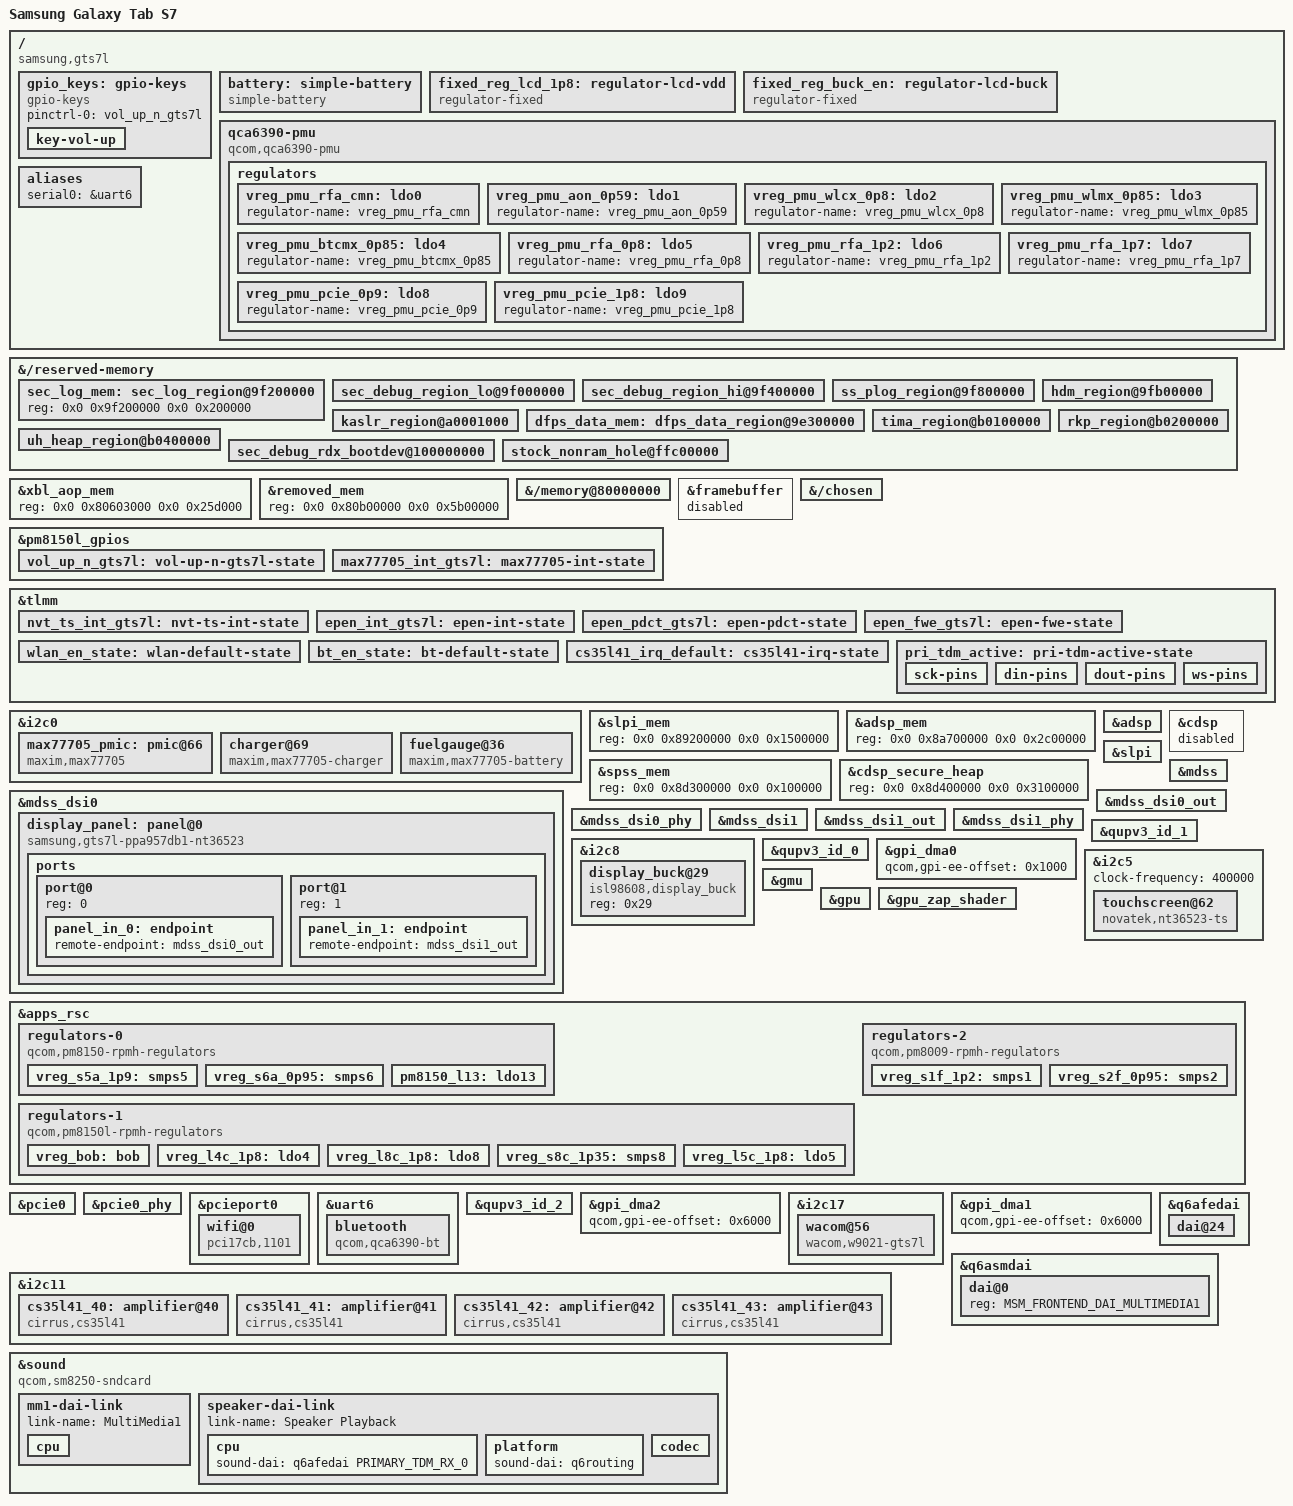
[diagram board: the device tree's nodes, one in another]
// SPDX-License-Identifier: GPL-2.0-only
/*
 * Samsung Galaxy Tab S7 LTE (SM-T875, "gts7l")
 *
 * Forked from upstream's sm8250-samsung-common.dtsi (shared Samsung SM8250
 * phone platform base: PM8150 PMIC, ADSP/CDSP/SLPI scaffolding, base
 * regulators) per the decision in docs/kernel-baseline.md. That base file is
 * phone-shaped (single volume-up key, phone-sized splash framebuffer) and is
 * overridden below wherever this tablet's actual hardware differs.
 *
 * Hardware facts below are sourced from two places, both cited inline:
 *   - Samsung's GPL kernel source for this device (T875XXU1ATK1),
 *     specifically the board-revision overlay that matches our physical
 *     unit's `androidboot.revision=7`:
 *     references/gts7l/arch/arm64/boot/dts/samsung/gts7l/
 *       kona-sec-gts7l-eur-overlay-r07.dts
 *   - Live confirmation pulled directly off the physical tablet (rooted,
 *     stock T875XXU1ATK4) via `cat /proc/interrupts` and
 *     `cat /sys/kernel/debug/gpio`, cross-checked against the above.
 * See docs/hardware-inventory.md and docs/devicetree-notes.md for the full
 * writeup and provenance of every value below. Anything not confirmed by
 * both sources is marked TODO rather than guessed.
 */

/dts-v1/;

#include <dt-bindings/gpio/gpio.h>
#include <dt-bindings/input/input.h>
#include <dt-bindings/interrupt-controller/irq.h>
#include <dt-bindings/phy/phy.h>
#include <dt-bindings/regulator/qcom,rpmh-regulator.h>
#include <dt-bindings/sound/qcom,q6asm.h>
#include "sm8250-samsung-common.dtsi"

/*
 * Unlike the Galaxy S20 phones sm8250-samsung-common.dtsi was written for,
 * this tablet has a full three-PMIC complex (PM8150 + PM8150L + PM8009),
 * confirmed in docs/hardware-inventory.md from Samsung's own GPL source.
 * common.dtsi only pulls in pm8150.dtsi - add the other two here so the
 * &pm8150l_gpios references below (volume-up, S Pen, MAX77705 irq - all
 * confirmed wired to PM8150L, not PM8150) resolve. Both self-attach to
 * &spmi_bus internally, so #include is all that's needed.
 */
#include "pm8150l.dtsi"
#include "pm8009.dtsi"

/ {
	model = "Samsung Galaxy Tab S7";
	/*
	 * RETRACTED 2026-09-13 (Round 7, docs/kernel-boot-debugging.md): this
	 * 3-entry structure was believed fixed based on indirect evidence that
	 * turned out to be a methodology artifact (same class of mistake as
	 * the "confirmed baseline" retraction elsewhere in this project). A
	 * correctly-built, freshly-tested artifact using exactly this DTS
	 * still hits the identical "No match found for Soc Dtb type" failure,
	 * at a timestamp identical to the microsecond versus every other
	 * variant tried (single-entry, with/without msm-id, with/without
	 * `-@`). The structure below is kept because it correctly mirrors
	 * stock's real appended-DTB layout and isn't known to be wrong - just
	 * not confirmed to be the fix. Root cause of the ABL rejection is
	 * unknown again; don't trust the "fix" framing in the comment below
	 * without re-reading Round 7 first.
	 */
	/*
	 * `qcom,kona` + `qcom,msm-id` fix attempt #2 (2026-09-13), after
	 * attempt #1 (DTS-property-only, single DTB) made zero observable
	 * difference to the "No match found for Soc Dtb type" failure - see
	 * docs/kernel-boot-debugging.md Round 5 for the full comparison.
	 *
	 * Root cause found by extracting the STOCK boot.img's own `dtb`
	 * section (via magiskboot unpack) and inspecting it directly: it is
	 * not one DTB, it's **three plain FDT blobs concatenated
	 * back-to-back** (FDT magic 0xd00dfeed found at byte offsets 0,
	 * 519810, 1039616 - confirmed by hand, not assumed), one per `kona`
	 * silicon stepping this retail unit's kernel expects to possibly see:
	 *
	 *   entry 0: model "kona v2.1 SoC", qcom,msm-id = <0x164 0x20001>
	 *   entry 1: model "kona v2 SoC",   qcom,msm-id = <0x164 0x20000>
	 *   entry 2: model "kona v1 SoC",   qcom,msm-id = <0x164 0x10000>
	 *
	 * All three use plain `compatible = "qcom,kona";` and none carry
	 * `qcom,board-id` at all (board-id belongs to a separate per-board
	 * dtbo overlay, applied later in the boot chain - Samsung's real
	 * overlay for this exact unit is
	 * references/gts7l/arch/arm64/boot/dts/samsung/gts7l/
	 * kona-sec-gts7l-eur-overlay-r07.dts, `qcom,board-id = <0x8 0x7>`).
	 * `qcom,board-id` is deliberately NOT set here for that reason - it
	 * doesn't belong in this stepping-selection blob per stock's own
	 * structure, and attempt #1 including it here proved that placement
	 * doesn't help anyway.
	 *
	 * Attempt #1's single DTB only covered the v1 (0x10000) stepping -
	 * if this physical unit's actual fused silicon revision is v2 or
	 * v2.1 (which stock clearly hedges for by shipping all three), a
	 * lone v1 entry would never match, exactly reproducing the
	 * unmodified failure we saw. The fix built from this DTS (see
	 * docs/kernel-boot-debugging.md Round 5) concatenates three
	 * otherwise-identical builds of this DTB, one per stepping, mirroring
	 * stock's exact structure - see work/build-appended-dtb.sh (or the
	 * Round 5 writeup) for how that's assembled from this single source
	 * file via `fdtput` patching qcom,msm-id per copy.
	 *
	 * Sourcing: stock dtb extraction done locally this session;
	 * cross-checked against Samsung's own base platform file
	 * (references/gts7l/arch/arm64/boot/dts/vendor/qcom/kona.dtsi,
	 * `compatible = "qcom,kona"` + `qcom,msm-id = <356 0x10000>` i.e.
	 * 0x164 0x10000 - matches stock entry 2 exactly) and against the
	 * sibling S9 Ultra project's independently-documented fix for the
	 * identical ABL error string on the same Samsung-ABL family
	 * (references/postmarketos-galaxy-tab-s9-ultra/docs/porting-log.md).
	 *
	 * qcom,board-id ADDED 2026-09-13 (Round 8, docs/kernel-boot-debugging.md):
	 * Qualcomm's own official binding doc (referenced kernel source,
	 * arch/arm64/boot/dts/vendor/bindings/arm/msm/msm-id.txt) states
	 * explicitly that the 2-field short form of qcom,msm-id used here
	 * ("chipset_foundry_id, rev_id") REQUIRES qcom,board-id to also be
	 * defined - a plain documented requirement this DTS was missing
	 * entirely, independent of and much simpler than every DTB-matching
	 * theory chased before it. Stock's own kona.dtsi entries confirm this
	 * requirement (they pair the same 2-field msm-id form with SOME
	 * qcom,board-id value) - fixing "No match found for Soc Dtb type"
	 * (confirmed in Round 9) only needed the property to be *present*,
	 * value `<0x00 0x00>` (wildcard) was sufficient for that specific
	 * check.
	 *
	 * Changed to the real value 2026-09-13 (Round 9, docs/kernel-boot-
	 * debugging.md): after the fix above, a *separate, later* ABL stage
	 * ("Unable to find the Board Dtb" / "Error: Board Dtbo blob not
	 * found") was hit and is NOT satisfied by the wildcard value - proven
	 * across three independent `dtbo` partition content variations (all
	 * produced byte-identical failures), meaning this stage reads board
	 * identity from the *appended DTB itself*, not `dtbo`, and requires
	 * an exact match. Set to `<0x08 0x07>`, this physical unit's real
	 * fused board-id - confirmed via the real per-board overlay in stock's
	 * dtbo.img (`entry.7`, `qcom,board-id = <0x08 0x07>`) and independently
	 * via TWRP's own kernel `Hardware name: Samsung GTS7L PROJECT - PV
	 * REV0.4 (board-id,7)` dmesg line. `0x8` is the platform-type-id field
	 * (constant across all stock's per-region entries), `0x7` the
	 * board-revision field (the value specific to this exact unit's
	 * region/revision). Four independent DTBO content variations (Round 9)
	 * all failed identically even with this value set, tracing further
	 * confirmed board-id alone isn't the remaining blocker.
	 *
	 * qcom,pmic-id ADDED 2026-09-13 (Round 9, via Ghidra decompilation of
	 * the actual ABL matching function, LinuxLoader.pe FUN_00025700):
	 * disassembly revealed ABL treats our appended-DTB match as only
	 * "good enough", not "exact" - an exact match (a specific 6-bit
	 * combination in the match-quality flags word) is required to skip
	 * the strict per-region DTBO search entirely, which is what's
	 * actually failing ("Unable to find the Board Dtb"). One of those
	 * required bits (bit 18) comes from qcom,pmic-id's first cell
	 * matching the live hardware PMIC "model" register exactly - a
	 * property this DTS never had, so that bit could never be set.
	 *
	 * Value: <0x1e 0 0 0> - `0x1e` from the live kernel's own
	 * /sys/devices/soc0/pmic_model (65566 = 0x1001E, low byte = 0x1E),
	 * the closest real evidence available without ABL's own verbose
	 * logging (blocked - needs raw uefivarstore partition writes to set
	 * the standard EDK2 "EFIDebug" variable, not attempted). Per the
	 * matcher's own logic, each of the 4 cells packs one PMIC's
	 * {model: low byte, revision: upper 3 bytes} and this device has 3
	 * real PMICs (PM8150/PM8150L/PM8009) - only cell 0 (the primary
	 * PMIC, matching what the Linux sysfs value itself reports) needs to
	 * be an exact model match for the specific bit we need; a model
	 * value of 0 in the other cells is treated as a harmless wildcard by
	 * the same matcher, not an error. **Not yet hardware-tested** - the
	 * exact correspondence between this Linux-reported value and what
	 * ABL's own hardware read returns is unproven; see
	 * kernel-boot-debugging.md Round 9 for the full reasoning and what
	 * to try next if this specific value doesn't work.
	 */
	compatible = "samsung,gts7l", "qcom,kona", "qcom,sm8250";
	qcom,msm-id = <0x164 0x10000>;
	qcom,board-id = <0x08 0x07>;
	qcom,pmic-id = <0x1e 0x00 0x00 0x00>;
	chassis-type = "tablet";

	/*
	 * RETRACTED 2026-09-19 (Round 22, docs/kernel-boot-debugging.md): the
	 * "regression" described below was real but the context has changed
	 * completely - back then this whole DTB was what ABL itself had to
	 * accept (Rounds 4-11's entire fight), so any content change could
	 * plausibly affect ABL's own matching. Since Round 20/22's uniLoader
	 * pivot, this DTB is never seen by ABL at all - it's embedded
	 * directly in uniLoader's own binary and only reaches the real
	 * mainline kernel after uniLoader has already gotten full CPU control
	 * from a completely unrelated, unmodified stock DTB/DTBO. There is no
	 * remaining mechanism by which content here could affect ABL
	 * acceptance. Re-adding the framebuffer override below on that basis.
	 *
	 * Original note (2026-09-12, Round 5-era): a `chosen`/
	 * `simple-framebuffer` node reusing the ABL's real splash region was
	 * tried to get an on-screen boot console, since neither
	 * `/proc/last_kmsg` (bootloader-only) nor `console-ramoops-0` (only
	 * ever reflects whichever kernel is *currently* running) can show
	 * what our kernel does after handoff. Reverted at the time after an
	 * isolation test showed a regression - not revisited until now,
	 * because at the time it wasn't understood *why*, and the DTB itself
	 * was still the thing ABL had to accept.
	 */
};

/*
 * Round 29 (2026-09-19, docs/kernel-boot-debugging.md): reserve Samsung's
 * real `sec_log_buf` region (`sec_log=0x200000@0x9F200000`, confirmed
 * live via this device's own `/proc/cmdline`) so the kernel's own memory
 * allocator can never hand this physical range out to anything else -
 * `init/main.c`'s `early_sec_log_init()` writes this project's own early
 * printk output directly into it, byte-compatible with the format
 * TWRP's own `/proc/last_kmsg` already reads. `no-map` isn't set
 * deliberately (matching stock's own splash-region convention elsewhere
 * in this file) - `early_sec_log_write()` accesses it via a plain
 * `phys_to_virt()`, which needs this region to stay part of the kernel's
 * ordinary linear map, not excluded from it.
 */
&{/reserved-memory} {
	sec_log_mem: sec_log_region@9f200000 {
		reg = <0x0 0x9f200000 0x0 0x200000>;
	};
};

/*
 * Round 34 (2026-09-19, docs/kernel-boot-debugging.md): the S9 Ultra
 * mainline porting project hit our exact symptom class (Linux boots,
 * console/logo visible, then dies with zero pstore/panic evidence) and
 * traced an early instance of it to `TZBSP_ERR_FATAL_NOC_ERROR` - Linux
 * touching a physical range Samsung's stock DTBO normally reserves but
 * their minimal upstream DTB didn't carry. Our own DTS has the same gap:
 * pulled this device's *live* `/reserved-memory` node straight off real
 * hardware (`adb shell` against a TWRP boot, which uses the same
 * ABL-merged stock DTB/DTBO as normal boot) and diffed it against what
 * upstream's `sm8250.dtsi` + `sm8250-samsung-common.dtsi` already
 * declare (`work/round34-reserved-mem/live-reserved-memory.txt`).
 *
 * Everything below is either populated by ABL/XBL/TrustZone before any
 * kernel choice is even made (so it's live/protected the same way
 * whether Samsung's downstream kernel or our own mainline one is
 * running), or is a case where upstream's own static node undershoots
 * what this specific device's firmware actually protects. The `pil_*`
 * remoteproc firmware regions were also compared and found shifted vs.
 * upstream, but were deliberately left alone: those addresses are only
 * ever touched by an active PIL/remoteproc driver requesting them, none
 * of which this Phase 1 kernel enables, and we have direct proof
 * (`docs/kernel-boot-debugging.md` Round 30+) that code executing from
 * uniLoader's own `PAYLOAD_ENTRY` - which happens to sit inside the
 * live `cdsp_secure_heap` range - runs correctly for many seconds, so
 * that particular overlap isn't hardware-enforced against us. These are:
 *
 *  - sec_debug_region@0x9f000000 (8 MiB) actually encloses our own
 *    sec_log_region above; reserved here as the two flanking pieces so
 *    the two nodes don't overlap.
 *  - ss_plog_region, hdm_region, kaslr_region: small, unconditional
 *    Samsung/TZ carveouts right next to sec_log/ramoops, entirely
 *    unreserved in our DTB until now.
 *  - dfps_data_region@0x9e300000 sits immediately after
 *    cont_splash_mem/our simple-framebuffer's own carveout ends -
 *    exactly the kind of neighbor worth reserving given our current
 *    unsolved "screen goes black right after simplefb registers"
 *    symptom.
 *  - tima_region/rkp_region/uh_heap_region: contiguous
 *    0xb0100000-0xb1800000, Samsung's kernel-protection carveouts.
 *  - sec_debug_rdx_bootdev@0x100000000: a large (173 MiB) live
 *    reservation with no upstream equivalent at all.
 */
&{/reserved-memory} {
	sec_debug_region_lo@9f000000 {
		reg = <0x0 0x9f000000 0x0 0x200000>;
		no-map;
	};

	sec_debug_region_hi@9f400000 {
		reg = <0x0 0x9f400000 0x0 0x400000>;
		no-map;
	};

	ss_plog_region@9f800000 {
		reg = <0x0 0x9f800000 0x0 0x200000>;
		no-map;
	};

	hdm_region@9fb00000 {
		reg = <0x0 0x9fb00000 0x0 0x1000>;
		no-map;
	};

	kaslr_region@a0001000 {
		reg = <0x0 0xa0001000 0x0 0x1000>;
		no-map;
	};

	dfps_data_region@9e300000 {
		reg = <0x0 0x9e300000 0x0 0x100000>;
		no-map;
	};

	tima_region@b0100000 {
		reg = <0x0 0xb0100000 0x0 0x100000>;
		no-map;
	};

	rkp_region@b0200000 {
		reg = <0x0 0xb0200000 0x0 0x200000>;
		no-map;
	};

	uh_heap_region@b0400000 {
		reg = <0x0 0xb0400000 0x0 0x1400000>;
		no-map;
	};

	sec_debug_rdx_bootdev@100000000 {
		reg = <0x1 0x00000000 0x0 0xad00000>;
		no-map;
	};
};

/*
 * Round 34: upstream's static `xbl_aop_mem`/`removed_mem` nodes both
 * undershoot what this device's live firmware actually protects -
 * confirmed via the same live `/reserved-memory` pull above. Real live
 * xbl_aop starts a full ~0xfd000 (~1 MiB) earlier than upstream's
 * `0x80700000`, and removed_mem is 0x800000 (8 MiB) bigger than
 * upstream's `0x5300000`. Overriding both by their upstream labels to
 * match the live values exactly, rather than adding overlapping nodes.
 */
&xbl_aop_mem {
	reg = <0x0 0x80603000 0x0 0x25d000>;
};

&removed_mem {
	reg = <0x0 0x80b00000 0x0 0x5b00000>;
};

/*
 * Round 23 (2026-09-19, docs/kernel-boot-debugging.md): pulled Samsung's
 * persistent `/dev/block/by-name/debug` ramdump-summary partition (a
 * genuine, real crash-history log spanning many prior resets - unlike
 * `/proc/last_kmsg`'s small ring buffer, found via online research the
 * owner asked for after confirming no UART hardware was available)
 * directly off the physical device from TWRP. It captured a real Linux
 * kernel panic from one of the Round 20-22 uniLoader boot attempts, with
 * a full backtrace pointing at `out_of_memory` / `__alloc_pages_nodemask`
 * / `handle_pte_fault` / `do_page_fault` - a real, textbook Linux
 * page-fault-triggers-allocation-triggers-OOM call chain, panic message
 * "System is deadlocked on memory". Root cause found directly:
 * upstream's `sm8250.dtsi` root `memory@80000000` node ships with
 * `reg = <0x0 0x80000000 0x0 0x0>` (zero size) and an explicit comment,
 * "We expect the bootloader to fill in the size" - normally patched
 * dynamically by ABL at boot time, but uniLoader's `patch_dtb()` only
 * ever adds `linux,initrd-start`/`-end`, never touches memory size. This
 * project's own compiled DTB confirmed carrying that exact zero-size
 * placeholder through unmodified. The real kernel was booting believing
 * it had zero bytes of usable RAM - a complete, sufficient explanation
 * for the observed OOM panic, independent of anything display/cmdline
 * related (Round 21-22's fixes never had a chance to matter). Real size
 * confirmed directly from this device's own hardware log
 * (`work/last_kmsg_*.txt`, XBL: "Rank 0 size = 6144 MB, Rank 1 size =
 * 0 MB"), base address matches the placeholder's own existing `0x80000000`.
 */
/*
 * PM8150 RTC (2026-09-22): the hardware clock exists and is enabled in
 * pm8150.dtsi, but was never usable - CONFIG_RTC_DRV_PM8XXX was =m (now
 * =y in kernel/config/gts7l.fragment), so there was no rtc0 at boot and
 * every boot started at 1970. It's read-only for Linux: tested with
 * allow-set-time, and the PMIC arbiter refused the write ("disallowed
 * SPMI write to sid=0, addr=0x6046" - write access belongs to another
 * execution environment, as on stock Android). So no allow-set-time
 * here; wall-clock time across reboots comes from a userspace offset
 * (tools/rootfs/rtc-offset/, same idea as Android's time daemon).
 */

&{/memory@80000000} {
	/*
	 * 2026-09-22 (CPU hard-hang investigation, docs/kernel-boot-debugging.md):
	 * the single flat 6 GiB range above was wrong. This device's live,
	 * ABL-filled `/proc/device-tree/memory/reg` (pulled from TWRP) is two
	 * ranges with a 52 MiB hole at 0xbcc00000-0xbfffffff, and stock's
	 * `/proc/iomem` agrees (System RAM ends at 0xbcbfffff, resumes at
	 * 0xc0000000). Our kernel was handing that hole out as ordinary pages.
	 * It sits below 4 GiB, so the page allocator only reaches it once
	 * ZONE_NORMAL is under pressure - or immediately with mem=2G - which
	 * matches the "memory pressure -> CPU stops answering even NMI" hang.
	 * Copied exactly from the live value.
	 */
	reg = <0x0 0x80000000 0x0 0x3cc00000>,
	      <0x0 0xc0000000 0x1 0x40000000>;
};

/*
 * 2026-09-22, same investigation: the other ranges a full diff of our
 * usable RAM against stock's `/proc/iomem` "System RAM" turned up (Round
 * 34 only diffed `/reserved-memory`, never the memory node or the actual
 * resulting RAM map):
 *
 *  - (The live `cdsp_secure_heap`, 0x90400000-0x94a00000, also differs
 *    from upstream's 0x8bf00000 node. A no-map node for it was tried and
 *    removed: it can't reserve because uniLoader's FDT already sits at
 *    ~0x939a8000 inside it, and ABL loading/running uniLoader from
 *    ~0x90600000-0x93a2xxxx shows that range is accessible at boot.)
 *  - 0xffc00000-0xffc1ffff (128 KiB) is inside ABL's memory range but
 *    excluded from stock's System RAM by something outside
 *    `/reserved-memory`; unknown owner, reserved to match stock.
 */
&{/reserved-memory} {
	stock_nonram_hole@ffc00000 {
		reg = <0x0 0xffc00000 0x0 0x20000>;
		no-map;
	};
};

/*
 * Round 22 (2026-09-19, docs/kernel-boot-debugging.md): uniLoader confirmed
 * working end to end on real hardware (its own splash/console prints
 * correctly, reaches "Booting kernel..." and jumps) - but nothing visible
 * happens after that, and there's no way yet to tell whether the real
 * kernel is silently working fine (just genuinely has no configured
 * console) or has crashed. Overriding the inherited phone-resolution
 * `framebuffer` node from `sm8250-samsung-common.dtsi` (1080x2400,
 * upstream's Galaxy S20 default) with this tablet's real panel geometry -
 * the node's `reg`/`format` are already correct (same physical splash
 * region ABL itself draws to, `cont_splash_region@9c000000`, already
 * `no-map`'d in `/reserved-memory` by the same shared base file). Also
 * forcing a real cmdline via `chosen/bootargs` here (uniLoader's own
 * `patch_dtb()` only adds `linux,initrd-start`/`-end`, never touches
 * `bootargs`) - `CONFIG_CMDLINE_FORCE` in `kernel/config/gts7l.fragment`
 * is a second, independent way to guarantee this reaches the kernel
 * regardless of what devicetree merging does.
 */
&framebuffer {
	width = <1600>;
	height = <2560>;
	stride = <(1600 * 4)>;
	/*
	 * Round 38 test (2026-09-19, docs/kernel-boot-debugging.md): disabled
	 * now that a real panel driver exists (samsung,gts7l-ppa957db1-nt36523
	 * above). simple-framebuffer registers early and unconditionally, with
	 * no dependency chain at all - it almost certainly wins the race to
	 * become fbcon's console (/dev/fb0) before the real DRM/MSM device
	 * even finishes probing (it has a long dependency chain: dispcc,
	 * i2c8, several regulators). If fbcon never switches over to the real
	 * DRM device, the panel driver's own .prepare()/backlight path is
	 * never actually invoked by anything, while dispcc's probe() still
	 * unconditionally reprograms the display PLLs (same as Round 33) -
	 * this would produce exactly the "kernel boot text blinks via
	 * simplefb, then blanks" symptom the owner saw, indistinguishable
	 * from Round 33's old bug, while the new panel work never even
	 * engages. Disabling this node removes the competing early fbdev
	 * device entirely so the real DRM/MSM generic fbdev-emulation
	 * (CONFIG_DRM_MSM_KMS_FBDEV) is the only console candidate.
	 */
	status = "disabled";
};

&{/chosen} {
	/* Round 22's belt-and-suspenders copy - CONFIG_CMDLINE_FORCE=y in
	 * kernel/config/gts7l.fragment is the string that actually wins,
	 * kept in sync manually.
	 */
	bootargs = "console=tty0 loglevel=15 clk_ignore_unused";
};

/*
 * Volume Up is wired to PM8150L (the companion/"L" PMIC), not PM8150
 * (primary) as on the common.dtsi's Galaxy S20 phone reference. Confirmed
 * via the GPL overlay's DT symbol table entry:
 *   key_vol_up_default = ".../qcom,pm8150l@4/pinctrl@c000/key_vol_up/..."
 * i.e. pin "gpio3" on pm8150l, not pm8150. Also cross-confirmed live:
 * `/proc/interrupts` shows `volume_up` on the `pmic_arb` domain, and
 * `/sys/kernel/debug/gpio`'s pm8150l gpiochip (gpiochip2, GPIOs 1085-1093)
 * has gpio3 configured as an input with a pull-up - consistent with a
 * button line, not a phone's pm8150 gpio3 wiring.
 *
 * This overrides (not extends) the inherited common.dtsi gpio_keys node,
 * which points at &vol_up_n on the wrong PMIC for this board.
 */
/delete-node/ &gpio_keys;

/ {
	gpio_keys: gpio-keys {
		compatible = "gpio-keys";

		pinctrl-names = "default";
		pinctrl-0 = <&vol_up_n_gts7l>;

		key-vol-up {
			label = "Volume Up";
			gpios = <&pm8150l_gpios 3 GPIO_ACTIVE_LOW>;
			linux,code = <KEY_VOLUMEUP>;
			debounce-interval = <15>;
			linux,can-disable;
			wakeup-source;
		};
	};
};

&pm8150l_gpios {
	vol_up_n_gts7l: vol-up-n-gts7l-state {
		pins = "gpio3";
		function = "normal";
		power-source = <0>;
		input-enable;
		bias-pull-up;
	};
};

/*
 * Volume Down and Power both ride the PM8150 PON block's resin/pwrkey
 * lines, already wired up correctly by sm8250-samsung-common.dtsi
 * (&pon_pwrkey, &pon_resin -> KEY_VOLUMEDOWN) - confirmed live via
 * `/proc/interrupts` showing `pon_kpdpwr_status` and `pon_resin_status` on
 * the pmic_arb domain. No override needed here.
 */

/*
 * Touchscreen: Novatek NT36523 TDDI (same IC drives the display panel -
 * see docs/hardware-inventory.md). Wired in Samsung's DT as "novatek,nvt-ts",
 * not yet backed by a mainline driver/binding - this node records the real
 * wiring now so the binding can be filled in during Phase 2 without
 * re-deriving it.
 *
 * irq-gpio = tlmm 15, confirmed two independent ways:
 *   - GPL overlay: `novatek,irq-gpio = <0xffffffff 0xf 0x2002>` (0xf = 15)
 *   - Live: `/proc/interrupts` shows `nvt-ts` on `msmgpio 15`, Edge
 * TODO(phase2): I2C bus/address (reg = <0x62> per the GPL source, bus
 * segment not yet identified), reset-gpio, and VDD/VCC-I2C supply rails are
 * not yet confirmed - the GPL node only specifies the irq line and firmware
 * blob name (novatek,firmware_name = "tsp_novatek/nt36523_gts7l.bin").
 */
&tlmm {
	nvt_ts_int_gts7l: nvt-ts-int-state {
		pins = "gpio15";
		function = "gpio";
		bias-disable;
	};
};

/*
 * S Pen: Wacom W90xx-series EMR digitizer over I2C (reg = <0x56> per the
 * GPL source). No BLE - this is a plain passive digitizer, unlike the S9
 * Ultra project's BLE-capable S Pen.
 *
 * All three GPIOs below are confirmed two independent ways:
 *   - GPL overlay: irq-gpio=0x88(136), pdct-gpio=0x7(7), fwe-gpio=0x6(6)
 *   - Live: `/proc/interrupts` shows `sec_epen_irq` on `msmgpio 136`
 *     (Level) and `sec_epen_pdct` on `msmgpio 7` (Edge)
 * AVDD supply confirmed from a second instance of this node in the GPL
 * source tree: `wacom,regulator_avdd = "pm8150_l13"` - i.e. PM8150 LDO13.
 * Not yet mapped to a mainline regulator phandle/supply property.
 *
 * TODO(phase4, tracks roadmap Phase 4): actual mainline driver binding
 * (upstream has no "wacom,w90xx" binding yet - closest is the generic
 * Wacom I2C digitizer support, needs evaluation), IC type 0x233d and
 * boot_addr 0x9 (bootloader-mode alternate address) recorded above for
 * whoever writes that driver glue.
 */
&tlmm {
	epen_int_gts7l: epen-int-state {
		pins = "gpio136";
		function = "gpio";
		bias-disable;
	};

	epen_pdct_gts7l: epen-pdct-state {
		pins = "gpio7";
		function = "gpio";
		bias-disable;
	};

	epen_fwe_gts7l: epen-fwe-state {
		pins = "gpio6";
		function = "gpio";
		bias-disable;
	};
};

/*
 * Charger + fuel gauge + MUIC + haptics: Maxim MAX77705 (reg = <0x66> per
 * the GPL source). irq-gpio confirmed two independent ways:
 *   - GPL overlay: `max77705,irq-gpio = <0x92 0xb 0x1>` - phandle 0x92
 *     resolves (via the same overlay's own symbol table) to the PM8150L
 *     gpio-controller node, pin 11 ("gpio11"), active-low.
 *   - Live: `/sys/kernel/debug/gpio`'s pm8150l gpiochip (gpiochip2) shows
 *     gpio11 configured as an input with a pull-up, consistent with an
 *     active-low interrupt line. `/proc/interrupts` additionally shows a
 *     large family of `max77705` interrupt names (chgin-irq, fuelgauge-irq,
 *     muic-*, pd-*, usbc-* etc.) all live and firing on the running stock
 *     kernel, confirming this is the real, active charger/PD/MUIC chip.
 *
 * Correction (docs/phase3-battery-scoping.md): the TODO above was
 * wrong - mainline gained a real "maxim,max77705" driver since this
 * comment was written (CONFIG_MFD_MAX77705, drivers/mfd/max77705.c,
 * compatible string matches downstream byte-for-byte) plus
 * CONFIG_CHARGER_MAX77705 (drivers/power/supply/max77705_charger.c)
 * for charging status (plugged in / charging / not). No fuel-gauge
 * sub-device exists in mainline's max77705_devs[] cell list at all
 * though - battery-percentage reporting is a real, separate,
 * from-scratch driver port (comparable in scope to the touchscreen
 * driver), deliberately out of scope here; this is charging-status
 * only. I2C bus confirmed this session: downstream's fixup table maps
 * this chip's fragment to `qupv3_se0_i2c`, i.e. mainline's `i2c0`
 * (`&qupv3_id_0`/`&gpi_dma0`, both already enabled for touch above).
 * `monitored-battery` is nominally `required` by the charger binding
 * but the driver only reports online/status, not capacity - omitted
 * for now; add a `simple-battery` node if probe rejects its absence.
 */
&pm8150l_gpios {
	max77705_int_gts7l: max77705-int-state {
		pins = "gpio11";
		function = "normal";
		power-source = <0>;
		input-enable;
		bias-pull-up;
	};
};

/*
 * Real hardware test (round84-build) found two more real gaps beyond
 * the DTS/Kconfig work above, neither guessed at:
 *
 * 1. Rev.0x2 rejected by mainline's own MFD probe (drivers/mfd/
 *    max77705.c only accepted MAX77705_PASS3) - this unit's real
 *    silicon is PASS2, confirmed via a clean regmap read of the
 *    revision register, and Samsung's own downstream driver
 *    (references/gts7l/drivers/mfd/max77705*.c) treats PASS2 as a
 *    fully normal, supported revision throughout - patched mainline
 *    to accept it too (see the patched drivers/mfd/max77705.c itself
 *    for the full comment).
 *
 * 2. The charger doesn't actually bind as an MFD sub-cell of pmic@66
 *    at all, despite mainline's own binding *example* nesting it that
 *    way in nt36xxx.c... no, in maxim,max77705.yaml - its driver
 *    (drivers/power/supply/max77705_charger.c) is a genuine
 *    `module_i2c_driver`, needing a real, separate i2c_client of its
 *    own, not a platform_device the MFD framework creates. Confirmed
 *    live: the MFD-nested `charger {}` sub-node created a real
 *    platform_device (visible in sysfs, correct modalias) but with
 *    *no* driver ever bound to it - `max77705-charger` never even
 *    appeared under `/sys/bus/platform/drivers/`, because
 *    `module_i2c_driver` registers on the I2C bus, not the platform
 *    bus. The *charger power-supply* binding's own example
 *    (maxim,max77705.yaml, not the MFD one) shows exactly this: a
 *    sibling `charger@69` node directly under the i2c bus, not nested
 *    under `pmic@66`. `0x69` independently confirmed real for this
 *    exact chip via downstream's own `I2C_ADDR_CHG = (0xD2 >> 1)`
 *    (references/gts7l/drivers/mfd/max77705.c:45) - byte-for-byte the
 *    same address mainline's own doc example uses, not a coincidence.
 *
 * `monitored-battery` really is required at runtime, not just by the
 * DT schema - `max77705_charger_initialize()` calls
 * `power_supply_get_battery_info()` unconditionally and bails the
 * whole probe on failure. A minimal `simple-battery` node (no real
 * capacity/voltage data - this pass is charging-status only, not fuel
 * gauge) satisfies it.
 */
/ {
	battery: simple-battery {
		compatible = "simple-battery";
	};
};

&i2c0 {
	status = "okay";

	max77705_pmic: pmic@66 {
		compatible = "maxim,max77705";
		reg = <0x66>;
		interrupt-parent = <&pm8150l_gpios>;
		interrupts = <11 IRQ_TYPE_LEVEL_LOW>;
		interrupt-controller;
		#interrupt-cells = <1>;
		pinctrl-names = "default";
		pinctrl-0 = <&max77705_int_gts7l>;
	};

	charger@69 {
		compatible = "maxim,max77705-charger";
		reg = <0x69>;
		monitored-battery = <&battery>;
		/*
		 * Interrupt 0 out of pmic@66's own interrupt-controller,
		 * per the binding's own documented mapping
		 * ("0 - charger", Documentation/devicetree/bindings/mfd/
		 * maxim,max77705.yaml) - the charger driver's probe()
		 * needs a real i2c->irq to set up its own regmap IRQ chip
		 * (devm_regmap_add_irq_chip()), not left optional.
		 */
		interrupt-parent = <&max77705_pmic>;
		interrupts = <0>;
	};

	/*
	 * Battery percentage / fuel gauge (docs/phase3-fuelgauge-scoping.md).
	 * Not a driver port - mainline's existing MAX17042-family driver
	 * (drivers/power/supply/max17042_battery.c) already carries a real
	 * "maxim,max77705-battery" compatible entry, mapped to the
	 * MAXIM_DEVICE_TYPE_MAX17047 register variant - confirmed real
	 * prior art (its own author, Dzmitry Sankouski - the same person
	 * behind pmic@66/charger@69 above - originally wrote a standalone
	 * MAX77705 fuel-gauge driver, then switched to extending this
	 * shared driver instead, per that series' own changelog; the same
	 * pattern is independently proven for the related MAX77759 chip,
	 * fully merged in this same file). I2C address 0x36 independently
	 * confirmed for this exact chip via downstream's own
	 * `I2C_ADDR_FG = (0x6C >> 1)` (references/gts7l/drivers/mfd/
	 * max77705.c:46) - byte-for-byte the same address. Interrupt 2
	 * ("2 - fuelgauge") per the same documented MFD IRQ-source mapping
	 * charger@69's own interrupt 0 already uses successfully. Unlike
	 * the charger, this driver has no `monitored-battery`
	 * requirement at all - it computes capacity from the chip's own
	 * internal ModelGauge algorithm directly.
	 */
	fuelgauge@36 {
		compatible = "maxim,max77705-battery";
		reg = <0x36>;
		interrupt-parent = <&max77705_pmic>;
		interrupts = <2>;
		shunt-resistor-micro-ohms = <10000>;
	};
};

/*
 * Wi-Fi/BT combo: Qualcomm QCA6390 over PCIe (confirmed live -
 * `wlan_wake_irq` and the WLAN_CE_* MSI vectors sit on the `msm_pci_msi`
 * domain in /proc/interrupts, meaning this is the PCIe-attached ath11k
 * path, not SDIO). CONFIG_CNSS_QCA6390=y confirmed in Samsung's own
 * defconfig (docs/hardware-inventory.md).
 *
 * TODO(phase3): the actual PCIe root complex / wlan node instantiation
 * (&pcie1 or equivalent on this platform, enable/reset GPIOs, regulator
 * supplies) has not been identified yet - needs its own pass through the
 * GPL source's PCIe and regulator nodes, which are large and not yet
 * cross-referenced against a live confirmation the way the items above
 * were. Tracked as a Phase 3 task, not attempted in this first-pass DTS.
 */

/*
 * NOT YET ADDRESSED IN THIS FILE (left for their respective phases rather
 * than guessed at):
 *   - Display panel (Novatek NT36523 / PPA957DB1 WQXGA LCD) - Phase 2
 *   - Adreno 650 GPU enablement - Phase 2
 *   - microSD, USB host - Phase 4
 *   - Book Cover Keyboard (stm,touchpad / stm,keypad pogo-pin nodes) - Phase 5
 * See plans/roadmap.md for the phase breakdown these map to.
 */

/*
 * DSPs (2026-09-22, motion sensors stage 1 - docs/kernel-boot-debugging.md
 * "SLPI sensor hub, stage 1"). These nodes were "okay" before, but nothing
 * ever probed them: the PAS/GLINK/fastrpc drivers were all =m with no
 * /lib/modules on the rootfs, the firmware path had a capital "Samsung"
 * (the rootfs dir is lowercase), and no DSP firmware was installed at all.
 *
 * SLPI (sensor hub) only for now. Firmware is the stock split image
 * (slpi.mdt + slpi.b00-b20 from vendor firmware_mnt), which the PAS
 * loader takes directly. Its carveout is moved to where stock actually
 * loads it: live stock pil_slpi_region = 0x89200000 + 0x1500000 ("slpi:
 * loading from 0x89200000 to 0x8a700000", docs/logs/stock-boot-2026-09-22/
 * 07-slpi-sensorhub-remoteproc-trace.txt), not upstream's 0x88c00000 -
 * TrustZone validates the load region at PAS auth.
 *
 * CDSP stays disabled until its carveout is fixed the same way (stock
 * pil_cdsp_region = 0x8e300000 + 0x1a00000; ADSP was, see below).
 * 0x88c00000-0x89200000 becomes RAM, matching stock's /proc/iomem
 * (System RAM 86600000-891fffff).
 */
&slpi_mem {
	reg = <0x0 0x89200000 0x0 0x1500000>;
};

/*
 * Audio stage 0 (2026-09-22, docs/phase3-audio-scoping.md): ADSP moved to
 * stock's live placement, pil_adsp_region = 0x8a700000 + 0x2c00000
 * (TrustZone validates the load region at PAS auth, as for the SLPI).
 * That overlaps upstream's spss_mem (0x8be00000) and cdsp_secure_heap
 * (0x8bf00000), so both move too: spss_mem to stock's 0x8d300000, and
 * cdsp_secure_heap (referenced by nothing in mainline) becomes a
 * placeholder covering stock's npu/video/cvp/cdsp/camera/wlan/ipa/gpu
 * block up to the old heap end. 0x89200000-0x90500000 stays one
 * contiguous no-map range, matching stock's /proc/iomem.
 * gpu_mem is deliberately left at upstream's address: the Adreno zap
 * shader already loads fine there.
 */
&adsp_mem {
	reg = <0x0 0x8a700000 0x0 0x2c00000>;
};

&spss_mem {
	reg = <0x0 0x8d300000 0x0 0x100000>;
};

&cdsp_secure_heap {
	reg = <0x0 0x8d400000 0x0 0x3100000>;
};

&adsp {
	firmware-name = "qcom/sm8250/samsung/gts7l/adsp.mdt";
	status = "okay";
};

&cdsp {
	status = "disabled";
};

&slpi {
	firmware-name = "qcom/sm8250/samsung/gts7l/slpi.mdt";
	status = "okay";
};

/*
 * Round 17/18 (2026-09-17, docs/kernel-boot-debugging.md): after getting
 * ABL to accept this project's own mainline DTB cleanly (the S9 Ultra
 * project's invalidated-dtbo/DeviceTreeAppended technique), the device
 * started auto-resetting (`PM: HARD RESET by PS_HOLD`) immediately after
 * kernel handoff - closely paralleling a TrustZone NoC fault the S9 Ultra
 * project hit at this exact stage, caused by their mainline DTS missing
 * `/reserved-memory` carveouts their device's real firmware actually
 * protects.
 *
 * Audited this project's own compiled DTB against stock's real
 * `/reserved-memory` node (extracted directly from stock's boot.img `dtb`
 * section) address-by-address, not just by presence/absence. Found one
 * concrete, high-confidence mismatch: upstream's `sm8250.dtsi` reserves
 * `xbl_aop_mem` (Always-On Processor firmware memory - queried very early
 * in boot, during RPMh/power-domain setup) at `0x80700000`, size
 * `0x160000`. Stock's real firmware reserves `0x80603000`, size
 * `0x25d000` - same end address (`0x80860000`), but starting ~1MiB
 * *earlier*. That ~1MiB gap (`0x80603000`-`0x80700000`) is real,
 * secure-world-owned AOP firmware memory on this actual hardware that
 * upstream's generic reservation doesn't cover at all - our kernel's
 * buddy allocator could legitimately hand that range out to any driver,
 * which is exactly the kind of access that trips a NoC/TrustZone security
 * fault. This is the leading suspect for the Round 17 auto-reset.
 *
 * Also found `dfps_data_region@9e300000` (size 0x100000, dynamic
 * frame-rate tracking data) present in stock's reserved-memory list with
 * no upstream equivalent at all - added here too, matching stock's own
 * `no-map`-less (normal cached-accessible carveout, not excluded from the
 * linear map) treatment rather than guessing.
 *
 * Not yet re-tested on hardware as of writing this comment - see
 * kernel-boot-debugging.md for whichever Round actually confirms or
 * refutes this fixes the auto-reset.
 */
&xbl_aop_mem {
	reg = <0x0 0x80603000 0x0 0x25d000>;
};

&{/reserved-memory} {
	dfps_data_mem: dfps_data_region@9e300000 {
		reg = <0x0 0x9e300000 0x0 0x100000>;
	};
};

/*
 * Real hardware crash investigation (2026-09-20/21,
 * docs/kernel-boot-debugging.md): a genuine watchdog-detected hard CPU
 * lockup under sustained heavy 3D rendering load (Minecraft), preceded
 * by a DPU `[drm:dpu_crtc_frame_event_cb] *ERROR* crtc91 event 1
 * overflow` storm - but the hard reset kills the device before the
 * kernel can flush anything past the single "watchdog: ... hard
 * LOCKUP" line to the journal, leaving the actual stuck function
 * unknown. This project looked at pstore/ramoops once before, very
 * early on (Phase 1's Round 13 notes: "`/sys/fs/pstore/
 * console-ramoops-0` held only stale data... our DTS doesn't configure
 * a matching `ramoops` region"), but never came back to actually wire
 * it up until now that a real crash needs real forensics rather than
 * guessing from driver source alone.
 *
 * No new devicetree node needed at all: `sm8250-samsung-common.dtsi`
 * (this file's own base) already has a complete, real
 * `ramoops@9fa00000` node (1MB, `compatible = "ramoops"`, real
 * `record-size`/`console-size`/`ftrace-size`/`pmsg-size`, `no-map`) -
 * confirmed by decompiling this project's own built DTB, not assumed.
 * The only reason it never did anything is that `CONFIG_PSTORE`/
 * `PSTORE_RAM` were never enabled - the devicetree side of this was
 * quietly already correct. Enabling those below is the entire fix;
 * reusing this existing, upstream-vetted placement is safer than
 * picking a new manual address ourselves.
 */

/*
 * Round 35 (2026-09-19, docs/kernel-boot-debugging.md): the real,
 * mechanistically-confirmed cause of "screen goes black immediately
 * after `fb0: simplefb registered!`" (Round 33's `clk_ignore_unused` and
 * Round 34's reserved-memory audit both left this untouched, because
 * this isn't a devicetree-completeness problem at all).
 *
 * `CONFIG_SM_DISPCC_8250=y` is a *built-in* driver (no module loading
 * needed, unlike `CONFIG_DRM_MSM=m` which never gets loaded by this
 * minimal initramfs) - so it auto-probes unconditionally during normal
 * boot. Read `drivers/clk/qcom/dispcc-sm8250.c`'s own
 * `disp_cc_sm8250_probe()` directly: for our exact compatible string
 * ("qcom,sm8250-dispcc", not the sm8150/sm8350 variants handled
 * elsewhere in that function), it unconditionally calls
 * `clk_lucid_pll_configure(&disp_cc_pll0, ...)` and the same for pll1 -
 * reprogramming both display PLLs from scratch on every single probe,
 * with no check for "is this already locked and actively clocking
 * something". That's normal and expected on mainline *if* a real
 * MDSS/DPU/panel driver runs right after to redo the whole
 * power-sequenced re-init (GDSC, reset, PLL relock, panel commands) -
 * but we don't have one (`CONFIG_DRM_MSM=m`, never loaded here), so
 * dispcc tears down whatever PLL state ABL left actively driving this
 * LCD's video-mode DSI link, and nothing ever restores it. Unlike a
 * command-mode/self-refreshing AMOLED panel (which just keeps showing
 * its last frame from internal GRAM), a video-mode LCD panel - which is
 * genuinely what this tablet has, confirmed by the owner correcting an
 * earlier assumption - loses sync and blanks the instant the DSI host
 * stops actively streaming, which is exactly the "immediately after
 * simplefb registers" timing that's been observed since Round 32.
 *
 * Confirmed every consumer of `&dispcc`'s clocks/power-domain/resets in
 * `sm8250.dtsi` is an MDSS/MDP/DSI/DP child node, all only ever bound by
 * the same never-loaded `CONFIG_DRM_MSM` module - nothing built into
 * this kernel actually needs dispcc's clocks at boot. Disabling the node
 * entirely keeps its driver from probing (and thus from touching the
 * PLLs) for the rest of Phase 1; this is explicitly a stopgap for the
 * "leave ABL's splash content on screen" approach, not a real display
 * fix - actually driving the panel from Linux (Phase 2 scope) will need
 * dispcc probing properly alongside a real MDSS/DPU/panel driver that
 * redoes the full re-init sequence, not avoiding it.
 */
/*
 * Phase 2 (2026-09-19, docs/phase2-panel-scoping.md): re-enabling dispcc -
 * Round 35's disable was explicitly a Phase 1 stopgap (see the comment
 * above this one), needed only because nothing existed to redo the
 * power-sequenced re-init dispcc's own probe requires. Now that a real
 * panel driver exists (below), dispcc probing and reprogramming the
 * display PLLs is exactly the correct, needed behavior - the panel
 * driver's own prepare()/init_sequence does the actual re-init
 * afterward. No override needed - dispcc's default status in
 * sm8250.dtsi is already "okay" once this block is removed. This is
 * left in place as a comment purely as a pointer for anyone diffing
 * against the Round 35 state - there was no actual disable to reverse
 * by the time this file compiles, it's the absence of that override.
 */

/*
 * Phase 2 (2026-09-19, docs/phase2-panel-scoping.md): display bring-up -
 * Novatek NT36523 driving a CST PPA957DB1 WQXGA LCD panel, dual-DSI,
 * C-PHY, video mode. Every value below is sourced directly from
 * Samsung's own GPL kernel source and cross-checked, not assumed - see
 * docs/phase2-panel-scoping.md for the full recon writeup:
 *
 *  - Panel timings/DSI mode/lane count/physical size:
 *    references/gts7l/techpack/display/msm/samsung/NT36523_PPA957DB1/
 *    dsi_panel_NT36523_PPA957DB1_wqxga_video.dtsi
 *  - reset-gpio (tlmm 82), the two fixed regulators (tlmm 135 "lcd-vdd",
 *    tlmm 93 "lcd-buck"), and the ISL98608 bias IC's real bus
 *    (qupv3_se8_i2c, i.e. mainline's &i2c8 - NOT an i2c-gpio bus, that
 *    would have been a wrong assumption; confirmed via this overlay's
 *    own symbol table, `qupv3_se8_i2c = "/fragment@156:target:0"`):
 *    references/gts7l/arch/arm64/boot/dts/samsung/gts7l/
 *    kona-sec-gts7l-eur-overlay-r07.dts, fragments 152/155/156.
 *  - DSI controller/PHY analog supplies (vreg_l9a_1p2 / vreg_l5a_0p88,
 *    both PM8150 LDOs already declared by sm8250-samsung-common.dtsi's
 *    PMIC regulator nodes): cross-checked against this device's OWN
 *    downstream SoC-level file (not the panel-specific overlay),
 *    references/gts7l/arch/arm64/boot/dts/vendor/qcom/kona-sde.dtsi -
 *    `vdda-1p2-supply = <&pm8150_l9>;` on both mdss_dsi0/1,
 *    `vdda-0p9-supply = <&pm8150_l5>;` on both DSI PHYs. Independently
 *    matches Xiaomi's elish (a comparable mainline SM8250 tablet, see
 *    the scoping doc) using the exact same LDO numbers for the exact
 *    same rails - two different OEMs landing on the same PMIC LDO
 *    assignment strongly suggests this is Qualcomm's own SM8250
 *    reference-design wiring for these particular rails, not a
 *    coincidence.
 *  - The panel driver itself is a new compatible entry
 *    ("samsung,gts7l-ppa957db1-nt36523") added to mainline's existing
 *    drivers/gpu/drm/panel/panel-novatek-nt36523.c (not a new driver
 *    from scratch - that file already supports this exact chip family
 *    on Xiaomi's elish). Its on-command sequence was transcribed
 *    mechanically (a Python script, not hand-retyped) from the same
 *    downstream dtsi referenced above.
 */
&mdss {
	status = "okay";
};

&mdss_dsi0 {
	vdda-supply = <&vreg_l9a_1p2>;
	qcom,dual-dsi-mode;
	qcom,sync-dual-dsi;
	qcom,master-dsi;
	status = "okay";

	display_panel: panel@0 {
		compatible = "samsung,gts7l-ppa957db1-nt36523";
		reg = <0>;
		vddio-supply = <&fixed_reg_lcd_1p8>;
		reset-gpios = <&tlmm 82 GPIO_ACTIVE_LOW>;

		ports {
			#address-cells = <1>;
			#size-cells = <0>;

			port@0 {
				reg = <0>;

				panel_in_0: endpoint {
					remote-endpoint = <&mdss_dsi0_out>;
				};
			};

			port@1 {
				reg = <1>;

				panel_in_1: endpoint {
					remote-endpoint = <&mdss_dsi1_out>;
				};
			};
		};
	};
};

&mdss_dsi0_out {
	data-lanes = <0 1 2>;
	remote-endpoint = <&panel_in_0>;
};

&mdss_dsi0_phy {
	vdds-supply = <&vreg_l5a_0p88>;
	phy-type = <PHY_TYPE_CPHY>;
	status = "okay";

	/*
	 * Round 40 test (2026-09-19, docs/kernel-boot-debugging.md): real
	 * hardware showed "DSI PLL(0) lock failed, status=0x00000000" even
	 * with refgen fixed. Mainline's dsi_phy_7nm.c hardcodes generic
	 * PHY analog trim constants with no override mechanism upstream -
	 * added one (a project patch, mirroring dsi_phy_10nm.c's own
	 * existing `parse_dt_properties`/tuning_cfg precedent) and wired in
	 * Samsung's own board-specific calibration values from
	 * references/gts7l/techpack/display/msm/samsung/NT36523_PPA957DB1/
	 * dsi_panel_NT36523_PPA957DB1_wqxga_video.dtsi - see
	 * docs/phase2-panel-scoping.md for the full comparison against
	 * mainline's real (no-quirk-cphy) defaults.
	 */
	qcom,phy-vreg-ctrl-0 = <0x50>;
	qcom,phy-str-swi-cal-sel-ctrl = <0x04>;
	qcom,phy-rescode-offset-top-ctrl = <0x1f>;
	qcom,phy-rescode-offset-bot-ctrl = <0x1f>;
	/*
	 * Round 55 (docs/kernel-boot-debugging.md): downstream's dtsi also
	 * declares `samsung,phy_offset_mid_ctrl = <0x1F>` alongside top/bot
	 * - missed in Round 41's original transcription. Mainline's
	 * dsi_7nm_phy_enable() never wrote this register at all before this
	 * round.
	 */
	qcom,phy-rescode-offset-mid-ctrl = <0x1f>;
};

&mdss_dsi1 {
	vdda-supply = <&vreg_l9a_1p2>;
	qcom,dual-dsi-mode;
	qcom,sync-dual-dsi;
	/* DSI1 is slave, so use DSI0 clocks - same convention as elish. */
	assigned-clock-parents = <&mdss_dsi0_phy DSI_BYTE_PLL_CLK>,
				 <&mdss_dsi0_phy DSI_PIXEL_PLL_CLK>;
	status = "okay";
};

&mdss_dsi1_out {
	data-lanes = <0 1 2>;
	remote-endpoint = <&panel_in_1>;
};

&mdss_dsi1_phy {
	vdds-supply = <&vreg_l5a_0p88>;
	phy-type = <PHY_TYPE_CPHY>;
	status = "okay";

	/* Same PHY trim override as &mdss_dsi0_phy above - both PHYs on
	 * this board are the same silicon instance, same panel/trim.
	 */
	qcom,phy-vreg-ctrl-0 = <0x50>;
	qcom,phy-str-swi-cal-sel-ctrl = <0x04>;
	qcom,phy-rescode-offset-top-ctrl = <0x1f>;
	qcom,phy-rescode-offset-bot-ctrl = <0x1f>;
	qcom,phy-rescode-offset-mid-ctrl = <0x1f>;
};

/*
 * Two GPIO-controlled fixed regulators, matching Samsung's own
 * "fixed_reg_lcd_1p8"/"fixed_reg_buck_en" declarations exactly
 * (kona-sec-gts7l-eur-overlay-r07.dts fragment@155) - both
 * `regulator-boot-on` there too, so no explicit driver-side enable call
 * is needed for either; the regulator core turns them on during boot
 * before any consumer probes.
 *
 * Round 53 (docs/kernel-boot-debugging.md): confirmed live on real
 * hardware via `/sys/kernel/debug/regulator/lcd-buck` (state=disabled,
 * num_users=0) and `/sys/kernel/debug/gpio` (gpio93 reads "out low") -
 * "lcd-buck" has ZERO real consumers anywhere in this devicetree (no
 * `-supply` property references it, and downstream's own
 * isl98608_hw_i2c.c never calls regulator_get()/enable() on it either -
 * confirmed by grepping that source directly). `regulator-boot-on` only
 * marks it as already-on for the regulator core's *initial* accounting;
 * it does not stop mainline's own "disable unused regulators" late
 * cleanup pass from switching it back off once boot settles, since
 * nothing ever takes a real, counted reference on it. `lcd-vdd`
 * (fixed_reg_lcd_1p8) doesn't have this problem - the panel's own
 * `vddio-supply` reference keeps a genuine consumer holding it open for
 * as long as the panel is prepared, confirmed still "out high" on real
 * hardware well after boot. `lcd-buck` needs `regulator-always-on`
 * instead - downstream's own overlay has no driver-side enable call for
 * this rail either, so this is describing the same always-on hardware
 * intent in the one mainline devicetree idiom built for exactly this
 * case (a rail with no software-managed consumer that must never be
 * turned off), not a workaround.
 */
/ {
	fixed_reg_lcd_1p8: regulator-lcd-vdd {
		compatible = "regulator-fixed";
		regulator-name = "lcd-vdd";
		gpio = <&tlmm 135 GPIO_ACTIVE_HIGH>;
		enable-active-high;
		regulator-boot-on;
	};

	fixed_reg_buck_en: regulator-lcd-buck {
		compatible = "regulator-fixed";
		regulator-name = "lcd-buck";
		gpio = <&tlmm 93 GPIO_ACTIVE_HIGH>;
		enable-active-high;
		regulator-boot-on;
		regulator-always-on;
	};
};

/*
 * ISL98608 LCD bias IC (drivers/misc/isl98608-gts7l.c) - real hardware
 * QUP I2C instance qupv3_se8_i2c (mainline &i2c8), address 0x29, both
 * confirmed directly from the overlay rather than assumed (see the
 * comment block above).
 *
 * Round 48 (2026-09-19, docs/kernel-boot-debugging.md): &i2c8 alone was
 * never enough - confirmed on real hardware via
 * `ls /sys/bus/i2c/devices/` coming back completely empty even after
 * Round 47's CONFIG_QCOM_GPI_DMA fix. i2c8 is a CHILD of the QUP
 * wrapper node `qupv3_id_1: geniqup@ac0000` in sm8250.dtsi, which
 * itself defaults to `status = "disabled"` - a disabled parent means
 * of_platform_populate() never instantiates *any* of its children at
 * all, regardless of their own status. Confirmed this is the standard
 * mainline convention (not assumed): every other real i2c8/QUP1 user
 * enables the wrapper node itself alongside the specific bus.
 */
&qupv3_id_1 {
	status = "okay";
};

&i2c8 {
	status = "okay";

	display_buck@29 {
		compatible = "isl98608,display_buck";
		reg = <0x29>;
	};
};

/*
 * Touchscreen - Novatek NT36523 TDDI (the same physical chip as the LCD
 * panel; see docs/phase2-touchscreen-scoping.md for the full writeup).
 * QUP I2C instance qupv3_se5_i2c (mainline &i2c5), address 0x62, both
 * confirmed directly from Samsung's own GPL overlay
 * (kona-sec-gts7l-eur-overlay-r07.dts fragment@127 + its __fixups__
 * table), same as every other hardware fact in this file.
 *
 * &qupv3_id_0 (geniqup@9c0000, i2c5's parent QUP wrapper) needs the
 * exact same treatment Round 48 already found for i2c8/qupv3_id_1: it
 * defaults to `status = "disabled"` in sm8250.dtsi, and a disabled
 * parent means none of its children - i2c5 included - ever get
 * instantiated regardless of their own status.
 *
 * No separate reset-gpio: this TDDI chip's touch side has no reset
 * handling of its own at all (confirmed directly in the downstream
 * driver, references/gts7l/drivers/input/touchscreen/novatek/nt36523/
 * nt36xxx.c - no "reset-gpio"/"novatek,reset-gpio" property or GPIO
 * request anywhere) - it's entirely coupled to the panel's own existing
 * reset sequencing (GPIO 82, nt36523_reset() in
 * drivers/gpu/drm/panel/panel-novatek-nt36523.c).
 *
 * IRQ on GPIO 15 (`interrupts = <0xf 0x0>;` directly on the downstream
 * node), trigger type from nt36xxx.c's own default
 * (`IRQF_TRIGGER_LOW`, when no `novatek,irq-gpio` flags are parsed) ->
 * IRQ_TYPE_LEVEL_LOW here. No driver claims the "novatek,nt36523-ts"
 * compatible yet - this node alone won't bind to anything, but it
 * should be enough to confirm the chip enumerates on the bus
 * (`/sys/bus/i2c/devices/` should show `5-0062`) before any real driver
 * work starts, the same order Round 47/48 used for the ISL98608 bias
 * IC.
 *
 * First flash of this block only enabled &qupv3_id_0/&i2c5 and hit the
 * fourth instance of the exact "GPI DMA channel not available" bug this
 * project already found for i2c8 in Round 47 - confirmed live via
 * dmesg: `platform 994000.i2c: deferred probe pending: geni_i2c: Failed
 * to get tx DMA ch`. Unlike i2c8 (whose GENI SE instance has hardware
 * FIFO mode available and never actually requests a DMA channel - this
 * board's dts has never needed to touch `&gpi_dma1` for it), i2c5's SE
 * instance genuinely has no FIFO mode and requires a real, working GPI
 * DMA channel. `gpi_dma0` (the DMA controller instance i2c5's own
 * `dmas` property points at - a sibling node of `qupv3_id_0`, not one
 * of its children, so enabling the QUP wrapper alone doesn't cover it)
 * defaults to `status = "disabled"` in sm8250.dtsi just like every
 * other node in this recurring pattern.
 */
&qupv3_id_0 {
	status = "okay";
};

/*
 * Confirmed on real hardware: enabling this alone wasn't enough - i2c5
 * never enumerated at all, and dmesg showed a genuine hardware-level
 * failure (`gpi 900000.dma-controller: cmd: EV ALLOCATE completion
 * timeout`), not the usual "module never loaded" pattern. Added
 * temporary diagnostics directly in drivers/dma/qcom/gpi.c and confirmed
 * `devm_request_irq()` succeeds (irq=136) but the ISR never fires within
 * the 250ms timeout - the Linux/GIC side is fine, the hardware itself
 * never signals completion. Root cause: mainline hardcodes this
 * hardware's "EE" (execution environment) register-bank offset to 0x0
 * for the "qcom,sm8250-gpi-dma" compatible, but Samsung's own downstream
 * devicetree for this exact chip declares
 * `qcom,gpi-ee-offset = <0x1000>;` on this same node
 * (references/gts7l/arch/arm64/boot/dts/vendor/qcom/kona.dtsi) - this
 * offset is a TrustZone/XPU firmware configuration choice, not a fixed
 * SoC-generation constant, and different OEM firmware on the same SoC
 * can genuinely disagree. With the wrong offset, every register access
 * silently targeted the wrong EE's bank - writes didn't fault, but never
 * reached the real, active hardware, so no completion interrupt ever
 * fired. Fixed in drivers/dma/qcom/gpi.c to accept this exact devicetree
 * property as an override (falling back to the existing hardcoded table
 * for every other board), matching downstream's own property name.
 */
&gpi_dma0 {
	status = "okay";
	qcom,gpi-ee-offset = <0x1000>;
};

&i2c5 {
	status = "okay";
	/*
	 * 2026-09-22 (choppy touch): mainline's i2c-qcom-geni defaults
	 * to 100 kHz without this; stock logs "994000.i2c: Bus frequency not
	 * specified, default to 400KHz" for this same bus. At 100 kHz each
	 * 109-byte touch report takes ~10 ms - ~90% of the 11.4 ms frame
	 * at the chip's ~88 Hz IRQ rate - so reads can overrun the next
	 * frame and the chip keeps serving the old one.
	 */
	clock-frequency = <400000>;

	touchscreen@62 {
		compatible = "novatek,nt36523-ts";
		reg = <0x62>;
		interrupt-parent = <&tlmm>;
		/*
		 * Falling edge, matching stock (2026-09-22, choppy-touch fix):
		 * downstream's `novatek,irq-gpio = <... 15 0x2002>` flags are
		 * IRQF_ONESHOT | IRQF_TRIGGER_FALLING - its IRQF_TRIGGER_LOW
		 * is only a fallback for flag-less DTs - and stock's live
		 * /proc/interrupts shows this line as Edge (see the tlmm note
		 * above). The line idles LOW, so LEVEL_LOW fired continuously
		 * (~88/s at 100 kHz, ~357/s at 400 kHz, even with no finger
		 * down): back-to-back point-buffer reads at ~90% bus occupancy
		 * starved the chip's own frame updates, so positions only
		 * landed ~5 times/s.
		 */
		interrupts = <15 IRQ_TYPE_EDGE_FALLING>;
		pinctrl-names = "default";
		pinctrl-0 = <&nvt_ts_int_gts7l>;
	};
};

/*
 * Adreno 650 GPU (docs/phase2-gpu-scoping.md). sm8250.dtsi already fully
 * describes this GPU (gpu/gmu/gpucc/adreno_smmu, chip_ids 0x06050002 in
 * a6xx_catalog.c matching downstream's own `qcom,chipid = 0x06050000` for
 * this exact silicon) - just disabled by default like every other
 * peripheral in this recurring pattern. The only genuinely device-
 * specific piece is the zap-shader firmware: the GX power rail is behind
 * TrustZone, and adreno_zap_shader_load() authenticates a device-signed
 * blob through the PAS/SCM path before Linux can touch the GPU. Pulled
 * directly off this device's own `apnhlos` partition (mounted at
 * `/vendor/firmware_mnt` per `vendor/etc/fstab.qcom`) -
 * `a650_zap.mdt`/`.b00`/`.b01`/`.b02`, the standard PIL mdt+segments
 * split image mainline's own qcom_mdt_loader consumes directly, no
 * reassembly needed. `a650_sqe.fw`/`a650_gmu.bin` (generic, freely-
 * redistributable Qualcomm blobs, not device-signed) came from this
 * device's `/vendor/firmware` instead. Enablement recipe confirmed
 * against a real, shipping mainline device with the same GPU
 * (sm8250-xiaomi-elish-common.dtsi).
 */
&gmu {
	status = "okay";
};

&gpu {
	status = "okay";
};

&gpu_zap_shader {
	firmware-name = "qcom/sm8250/samsung/gts7l/a650_zap.mdt";
};

/*
 * Wi-Fi (Phase 3, docs/phase3-wifi-bt-scoping.md): Qualcomm QCA6390
 * ("Hastings") Wi-Fi 6 + Bluetooth combo, PCIe-attached. No driver of our
 * own is needed - mainline's `ath11k`/`ath11k_pci` plus the
 * `qcom,qca6390-pmu` power-sequencing driver (drivers/power/sequencing/
 * pwrseq-qcom-wcn.c) already fully support this exact chip. Adapted from
 * a real, shipping mainline board with the identical chip on the
 * identical SoC (arch/arm64/boot/dts/qcom/sm8250-xiaomi-elish-common.dtsi)
 * rather than written from scratch.
 *
 * The one real per-device fact that had to be pulled from Samsung's own
 * GPL source rather than copied from elish: this board's real
 * wlan-enable/bt-enable GPIOs. Downstream's base kona.dtsi (whose WLAN
 * node this tablet's board overlay attaches at &pcie0_rp, confirmed by
 * cross-referencing kona.dtsi's own `cnss_pci` sub-node against the
 * `wil6210` node's *disabled*, unrelated `qcom,pcie-parent = <&pcie1>`
 * elsewhere in the same file - easy to conflate at a glance) has this
 * board's real per-revision override for `wlan-en-gpio` at GPIO 90
 * (references/gts7l/.../kona-sec-gts7l-eur-overlay-r07.dts:11744,
 * `<0xffffffff 0x5a 0x0>` - 0x5a = 90), not the base tree's generic
 * GPIO 20 that elish (a different board) happens to also use. The
 * separate, real (`status = "ok"`), Samsung-specific `bt_qca6390` node in
 * that same overlay (:7513-7528, `compatible = "qca,qca6390",
 * "qca,qca6490"`) independently confirms GPIO 76 as `qca,bt-reset-gpio`
 * and gives this exact chip's real regulator voltage levels
 * (aon/dig/rfa1/rfa2 all match the separate `wlan` node's own
 * `vdd-wlan-*-config` values byte-for-byte, confirming both nodes
 * describe the same physical shared rails) - strong independent
 * confirmation this is real wiring, not a guess.
 *
 * Bluetooth itself is NOT wired up here yet: elish's own DTS (read in
 * full, not just its wifi@0/qca6390-pmu sections) shows BT actually
 * rides a separate UART (`&uart6 { bluetooth { compatible =
 * "qcom,qca6390-bt"; ... }; };`), not the PCIe link at all - a genuinely
 * different transport needing its own UART-instance research on this
 * board before it can be wired up. Deferred to a follow-up pass;
 * `docs/phase3-wifi-bt-scoping.md` needs a correction for this (it
 * initially concluded, incorrectly, that elish has no separate BT node).
 * `bt-enable-gpios` on the qca6390-pmu node below is still wired to the
 * real GPIO 76, since the PMU chip sequences power for both radios
 * together regardless of which transport BT ends up using.
 *
 * Calibration data (`qcom,calibration-variant` in elish) is deliberately
 * left unset for this first pass - per the scoping doc, the goal right
 * now is just confirming real PCIe enumeration with generic
 * linux-firmware.git blobs, before chasing this device's real
 * calibration data (which needs live-device extraction, same precedent
 * as the Adreno zap-shader above).
 */
&apps_rsc {
	regulators-0 {
		compatible = "qcom,pm8150-rpmh-regulators";
		qcom,pmic-id = "a";

		vdd-l3-l4-l5-l18-supply = <&vreg_s6a_0p95>;
		vdd-l6-l9-supply = <&vreg_s8c_1p35>;
		vdd-l7-l12-l14-l15-supply = <&vreg_s5a_1p9>;
		/*
		 * l13-l16-l17-supply source (&vreg_bob, PM8150L's Buck-Or-Boost
		 * rail, already defined below in regulators-1) matches
		 * Qualcomm's own SM8250 reference board
		 * (arch/arm64/boot/dts/qcom/sm8250-mtp.dts:196) - same PMIC,
		 * same LDO group, real sourced value, not guessed.
		 */
		vdd-l13-l16-l17-supply = <&vreg_bob>;

		vreg_s5a_1p9: smps5 {
			regulator-name = "vreg_s5a_1p9";
			regulator-min-microvolt = <1900000>;
			regulator-max-microvolt = <2040000>;
			regulator-initial-mode = <RPMH_REGULATOR_MODE_HPM>;
		};

		vreg_s6a_0p95: smps6 {
			regulator-name = "vreg_s6a_0p95";
			regulator-min-microvolt = <950000>;
			regulator-max-microvolt = <1128000>;
			regulator-initial-mode = <RPMH_REGULATOR_MODE_HPM>;
		};

		/*
		 * S Pen AVDD (docs/phase4-spen-scoping.md). Stock runs this
		 * rail at a fixed 3.3V in High Power Mode (live sysfs on stock:
		 * regulator.24 "pm8150_l13", consumer 10-0056, min = max =
		 * 3300000; downstream's r07 overlay sets min/max/init-voltage
		 * to 3.3V plus qcom,init-mode HPM).
		 *
		 * 3.3V itself is NOT representable here: mainline's
		 * pmic5_pldo table is 1.504V + n * 8mV, so the nearest steps
		 * are 3.296V and 3.304V (downstream sends raw millivolts to
		 * RPMh and never hits this). An earlier min = max = 3300000
		 * made set_machine_constraints() fail its apply_uV step, which
		 * fails regulator registration and takes the whole pm8150
		 * rpmh-regulator probe down - display and USB supplies
		 * included. That was the 2026-09-21 "brownout", not an
		 * electrical fault. Dropping the constraints stopped it but left
		 * the rail with no voltage vote at all, so the digitizer sat
		 * underpowered and NACKed every query. 3.296V fixes both.
		 *
		 * regulator-initial-mode/allowed-modes use the RPMh driver's
		 * own encoding (RPMH_REGULATOR_MODE_HPM = 3); the generic
		 * REGULATOR_MODE_* constants are silently ignored by its
		 * of_map_mode().
		 */
		pm8150_l13: ldo13 {
			regulator-name = "pm8150_l13";
			regulator-min-microvolt = <3296000>;
			regulator-max-microvolt = <3296000>;
			regulator-initial-mode = <RPMH_REGULATOR_MODE_HPM>;
			regulator-allowed-modes = <RPMH_REGULATOR_MODE_HPM>;
		};
	};

	/*
	 * PM8150L - this project's DTS already #includes pm8150l.dtsi (for
	 * &pm8150l_gpios, see the top of this file) but never actually
	 * defined its RPMH regulator nodes until now, since nothing needed
	 * one before. "c" as the qcom,pmic-id letter and every voltage
	 * range below match elish's own regulators-1 block exactly (a real
	 * PM8150L on the same SoC family) - only the two rails this board
	 * actually needs right now (smps8 for the WLAN/BT RFA2 rail, ldo5
	 * for the antenna switch) are given real, gts7l-specific voltage
	 * targets (from the confirmed downstream config values in the
	 * comment above); the rest of the block (vreg_bob and the
	 * vdd-*-supply chain) is structurally required scaffolding for the
	 * two rails to resolve, kept at elish's own safe range values
	 * since this project has no device-specific data for them yet.
	 */
	regulators-1 {
		compatible = "qcom,pm8150l-rpmh-regulators";
		qcom,pmic-id = "c";

		vdd-s1-supply = <&vph_pwr>;
		vdd-s2-supply = <&vph_pwr>;
		vdd-s3-supply = <&vph_pwr>;
		vdd-s4-supply = <&vph_pwr>;
		vdd-s5-supply = <&vph_pwr>;
		vdd-s6-supply = <&vph_pwr>;
		vdd-s7-supply = <&vph_pwr>;
		vdd-s8-supply = <&vph_pwr>;
		vdd-l1-l8-supply = <&vreg_s4a_1p8>;
		vdd-l2-l3-supply = <&vreg_s8c_1p35>;
		vdd-l4-l5-l6-supply = <&vreg_bob>;
		vdd-l7-l11-supply = <&vreg_bob>;
		vdd-l9-l10-supply = <&vreg_bob>;
		vdd-bob-supply = <&vph_pwr>;

		vreg_bob: bob {
			regulator-name = "vreg_bob";
			regulator-min-microvolt = <3350000>;
			regulator-max-microvolt = <3960000>;
			regulator-initial-mode = <RPMH_REGULATOR_MODE_AUTO>;
		};

		/*
		 * SLPI sensor rail (2026-09-22, motion sensors stage 2): stock's
		 * qcom,ssc@5c00000 node holds `sensor_vdd-supply = pm8150a_l8`
		 * at 1.8V (`qcom,sensor_vdd-uV-uA = <1800000 0>`, "active"
		 * reg). Mainline's SLPI node has no supply properties, so
		 * nothing held it: with hexagonrpcd serving the registry, the
		 * SLPI's sensor process crashed ~7s after every boot with
		 * "SEE Sensor exceeded processing time limit" (a sensor bus
		 * transaction to an unpowered chip). Always-on, like the Galaxy
		 * Tab S8 Ultra port's equivalent fix. 1.8V is an exact
		 * pmic5_pldo_lv step (1.504V + 37 * 8mV).
		 */
		/*
		 * Audio stage 2 (2026-09-22): stock's overlay pins pm8150a_l4 to a
		 * fixed 1.8V with regulator-always-on and no consumer, and it's
		 * enabled in TWRP (Samsung's kernel) while the CS35L41 amps answer
		 * there. The amps' VA (1.8V logic supply) is modelled on stock as
		 * a "dummy_vreg", i.e. an always-on board rail - this one. Without
		 * it, all four amps NACK their I2C address under mainline ("Failed
		 * waiting for OTP_BOOT_DONE", -ENXIO). 1.8V is an exact pmic5_pldo
		 * step (1.504V + 37 * 8mV).
		 */
		vreg_l4c_1p8: ldo4 {
			regulator-name = "vreg_l4c_1p8";
			regulator-min-microvolt = <1800000>;
			regulator-max-microvolt = <1800000>;
			regulator-always-on;
		};

		vreg_l8c_1p8: ldo8 {
			regulator-name = "vreg_l8c_1p8";
			regulator-min-microvolt = <1800000>;
			regulator-max-microvolt = <1800000>;
			regulator-always-on;
		};

		vreg_s8c_1p35: smps8 {
			regulator-name = "vreg_s8c_1p35";
			regulator-min-microvolt = <1350000>;
			regulator-max-microvolt = <1400000>;
			regulator-initial-mode = <RPMH_REGULATOR_MODE_HPM>;
		};

		/* Antenna switch supply (downstream: pm8150a_l5). */
		vreg_l5c_1p8: ldo5 {
			regulator-name = "vreg_l5c_1p8";
			regulator-min-microvolt = <1800000>;
			regulator-max-microvolt = <2800000>;
			regulator-initial-mode = <RPMH_REGULATOR_MODE_HPM>;
		};
	};

	/*
	 * PM8009 - same situation as PM8150L above: #included for
	 * &pm8009_gpios (MAX77705 irq) but never had its regulator nodes
	 * defined. "f" as the pmic-id letter and voltage ranges again match
	 * elish's own regulators-2 block; smps2 is the only rail this board
	 * currently needs (WLAN/BT digital core, downstream: pm8009_s2).
	 */
	regulators-2 {
		compatible = "qcom,pm8009-rpmh-regulators";
		qcom,pmic-id = "f";

		vdd-s1-supply = <&vph_pwr>;
		vdd-s2-supply = <&vreg_bob>;
		vdd-l2-supply = <&vreg_s8c_1p35>;
		vdd-l5-l6-supply = <&vreg_bob>;
		vdd-l7-supply = <&vreg_s4a_1p8>;

		vreg_s1f_1p2: smps1 {
			regulator-name = "vreg_s1f_1p2";
			regulator-min-microvolt = <1200000>;
			regulator-max-microvolt = <1200000>;
			regulator-initial-mode = <RPMH_REGULATOR_MODE_HPM>;
		};

		vreg_s2f_0p95: smps2 {
			regulator-name = "vreg_s2f_0p95";
			regulator-min-microvolt = <950000>;
			regulator-max-microvolt = <1100000>;
			regulator-initial-mode = <RPMH_REGULATOR_MODE_HPM>;
		};
	};
};

&tlmm {
	/*
	 * Idle/init pinctrl state only - matches elish's own pattern
	 * exactly (direction + bias set here, the qca6390-pmu driver itself
	 * drives the GPIO's actual level at runtime via gpiod_set_value()).
	 * GPIO numbers are this board's real, confirmed values (see the big
	 * comment above), not elish's GPIO 20/21.
	 */
	wlan_en_state: wlan-default-state {
		pins = "gpio90";
		function = "gpio";
		drive-strength = <16>;
		output-low;
		bias-pull-up;
	};

	bt_en_state: bt-default-state {
		pins = "gpio76";
		function = "gpio";
		drive-strength = <16>;
		output-low;
		bias-pull-up;
	};
};

/ {
	qca6390-pmu {
		compatible = "qcom,qca6390-pmu";

		pinctrl-names = "default";
		pinctrl-0 = <&bt_en_state>, <&wlan_en_state>;

		vddaon-supply = <&vreg_s6a_0p95>;
		vddpmu-supply = <&vreg_s6a_0p95>;
		vddrfa0p95-supply = <&vreg_s6a_0p95>;
		vddrfa1p3-supply = <&vreg_s8c_1p35>;
		vddrfa1p9-supply = <&vreg_s5a_1p9>;
		vddpcie1p3-supply = <&vreg_s8c_1p35>;
		vddpcie1p9-supply = <&vreg_s5a_1p9>;
		vddio-supply = <&vreg_s4a_1p8>;

		wlan-enable-gpios = <&tlmm 90 GPIO_ACTIVE_HIGH>;
		bt-enable-gpios = <&tlmm 76 GPIO_ACTIVE_HIGH>;

		regulators {
			vreg_pmu_rfa_cmn: ldo0 {
				regulator-name = "vreg_pmu_rfa_cmn";
			};

			vreg_pmu_aon_0p59: ldo1 {
				regulator-name = "vreg_pmu_aon_0p59";
			};

			vreg_pmu_wlcx_0p8: ldo2 {
				regulator-name = "vreg_pmu_wlcx_0p8";
			};

			vreg_pmu_wlmx_0p85: ldo3 {
				regulator-name = "vreg_pmu_wlmx_0p85";
			};

			vreg_pmu_btcmx_0p85: ldo4 {
				regulator-name = "vreg_pmu_btcmx_0p85";
			};

			vreg_pmu_rfa_0p8: ldo5 {
				regulator-name = "vreg_pmu_rfa_0p8";
			};

			vreg_pmu_rfa_1p2: ldo6 {
				regulator-name = "vreg_pmu_rfa_1p2";
			};

			vreg_pmu_rfa_1p7: ldo7 {
				regulator-name = "vreg_pmu_rfa_1p7";
			};

			vreg_pmu_pcie_0p9: ldo8 {
				regulator-name = "vreg_pmu_pcie_0p9";
			};

			vreg_pmu_pcie_1p8: ldo9 {
				regulator-name = "vreg_pmu_pcie_1p8";
			};
		};
	};
};

/*
 * PCIe0 - the controller instance gts7l's QCA6390 is really attached to
 * (confirmed above, not guessed from elish). &pcie0/&pcie0_phy are
 * defined in sm8250.dtsi already `status = "disabled"` by default - same
 * recurring "disabled at the SoC-dtsi level" pattern already solved for
 * &qupv3_id_0/&gpi_dma0 during touchscreen/panel bring-up. PHY analog
 * supplies reuse the same PM8150 rails already wired to the DSI PHYs
 * above (vreg_l5a_0p88/vreg_l9a_1p2) - matches elish exactly, and no new
 * regulator is needed since these are already-confirmed-working rails.
 */
&pcie0 {
	status = "okay";
};

&pcie0_phy {
	vdda-phy-supply = <&vreg_l5a_0p88>;
	vdda-pll-supply = <&vreg_l9a_1p2>;
	status = "okay";
};

&pcieport0 {
	wifi@0 {
		compatible = "pci17cb,1101";
		reg = <0x10000 0x0 0x0 0x0 0x0>;

		vddrfacmn-supply = <&vreg_pmu_rfa_cmn>;
		vddaon-supply = <&vreg_pmu_aon_0p59>;
		vddwlcx-supply = <&vreg_pmu_wlcx_0p8>;
		vddwlmx-supply = <&vreg_pmu_wlmx_0p85>;
		vddrfa0p8-supply = <&vreg_pmu_rfa_0p8>;
		vddrfa1p2-supply = <&vreg_pmu_rfa_1p2>;
		vddrfa1p7-supply = <&vreg_pmu_rfa_1p7>;
		vddpcie0p9-supply = <&vreg_pmu_pcie_0p9>;
		vddpcie1p8-supply = <&vreg_pmu_pcie_1p8>;
	};
};

/*
 * Bluetooth (docs/phase3-bluetooth-scoping.md) - same QCA6390 combo
 * chip as Wi-Fi above, but a genuinely separate UART transport, not
 * the PCIe link. Real UART instance confirmed two independent ways
 * (not guessed from the more obviously-named but unrelated
 * qupv3_se12_2uart): downstream's qupv3_se6_4uart carries
 * `qcom,wakeup-byte = <0xFD>`, the exact IBS wake byte mainline's own
 * hci_qca.c sends to QCA Bluetooth chips, and it's real 4-wire
 * (CTS/RTS/TX/RX) hardware flow control, unlike SE12's 2-wire
 * debug-console-shaped wiring. SE6 maps directly onto mainline's
 * &uart6 (byte-identical register address, sm8250.dtsi:1699), whose
 * default pinctrl state (GPIOs 16/17/18/19) already matches this
 * board's real pins exactly - no per-board pin override needed, same
 * "already correct at the SoC-reference-design level" situation
 * &pcie0's PERST/WAKE GPIOs were in. All six regulator supplies below
 * are the same qca6390-pmu-internal sub-nodes the Wi-Fi node above
 * already defines - copied from a real, shipping mainline board with
 * the same chip (sm8250-xiaomi-elish-common.dtsi) essentially
 * verbatim, since nothing here is gts7l-specific once the UART
 * instance itself is right.
 *
 * Real hardware test (round77-build) found one more real gap this
 * project had never needed before: qcom_geni_serial's probe()
 * requires an `aliases { serialN = ... }` entry (or a legacy
 * `hsuartN` one) to get a port "line" number at all -
 * `of_alias_get_id()` returning -ENODEV for both otherwise, logged as
 * the not-very-descriptive "qcom_geni_serial 998000.serial: Invalid
 * line -19". No `aliases { }` node existed anywhere in this project's
 * devicetree chain until now (confirmed by grepping this file and
 * sm8250-samsung-common.dtsi, neither has one) - never needed before
 * since &uart6 is the first UART this project has ever turned on.
 * elish has the exact same `serial0 = &uart6;` alias for the exact
 * same reason.
 */
/ {
	aliases {
		serial0 = &uart6;
	};
};

&uart6 {
	status = "okay";

	bluetooth {
		compatible = "qcom,qca6390-bt";

		vddrfacmn-supply = <&vreg_pmu_rfa_cmn>;
		vddaon-supply = <&vreg_pmu_aon_0p59>;
		vddbtcmx-supply = <&vreg_pmu_btcmx_0p85>;
		vddrfa0p8-supply = <&vreg_pmu_rfa_0p8>;
		vddrfa1p2-supply = <&vreg_pmu_rfa_1p2>;
		vddrfa1p7-supply = <&vreg_pmu_rfa_1p7>;

		/*
		 * Real hardware test (round79-build) found hci0 registers
		 * and loads real firmware successfully, but never becomes
		 * usable - stuck in the kernel's HCI_UNCONFIGURED state
		 * (confirmed via a raw mgmt-socket "Read Unconfigured
		 * Controller Index List" query, since bluetoothd's own
		 * "Controllers: 0" only checks the *configured* list).
		 * Root cause, found by reading btqca.c directly: this
		 * chip has no unique burned-in BD address - it reports a
		 * well-known QCA placeholder/default one instead
		 * (drivers/bluetooth/btqca.c's qca_check_bdaddr(),
		 * comparing against a hardcoded default and setting
		 * HCI_QUIRK_USE_BDADDR_PROPERTY when it matches), and
		 * mainline's own hci_core (net/bluetooth/hci_sync.c's
		 * hci_dev_get_bd_addr_from_property()) requires a real
		 * `local-bd-address` devicetree property before it'll
		 * treat the controller as configured/usable at all - a
		 * completely normal, expected situation for this chip
		 * family, not a bug. No real per-unit address exists to
		 * use (this isn't a factory-provisioned build), so this is
		 * a fixed, locally-administered address (bit 1 of the
		 * first octet set, per the standard IEEE local/universal
		 * bit - human-readable e6:2e:8b:7a:ca:29, stored
		 * byte-reversed per hci_dev_get_bd_addr_from_property()'s
		 * direct bacpy() into the LSB-first bdaddr_t - matches the
		 * byte order shown in the nxp,88w8987-bt.yaml binding
		 * example) rather than a real vendor-assigned one.
		 */
		local-bd-address = [29 ca 7a 8b 2e e6];
	};
};

/*
 * S Pen (Phase 4, docs/phase4-spen-scoping.md): Wacom W90xx-series EMR
 * digitizer, ic_type 0x233d. Driver support added upstream in
 * drivers/input/touchscreen/wacom_w9000.c (a new "wacom,w9021-gts7l"
 * variant plus tilt-axis reporting, confirmed field-for-field against
 * this device's own downstream driver - see the scoping doc and the
 * driver's own comment above that variant's definition).
 *
 * I2C bus resolved the same way as MAX77705's (line ~547 above):
 * downstream's overlay fixup table maps this node's fragment
 * (fragment@129) target to symbol `qupv3_se17_i2c`, i.e. mainline's
 * `&i2c17` (`i2c@88c000` in sm8250.dtsi - same SE-number convention
 * already confirmed for i2c0/MAX77705).
 *
 * irq-gpios and flash-mode-gpios reuse `epen_int_gts7l`/
 * `epen_fwe_gts7l` pinctrl states already defined and live-confirmed
 * above (tlmm 136 and tlmm 6 respectively - see that comment for the
 * two independent confirmations). IRQ_TYPE_LEVEL_HIGH follows from
 * those same two sources: the GPL overlay's third gpio-spec cell (`...
 * 0x88 0x0>`) is `0x0` = `GPIO_ACTIVE_HIGH`, and the live
 * `/proc/interrupts` confirmation independently says "Level" (as
 * opposed to touchscreen's own confirmed "Edge" trigger a few nodes
 * up) - not independently reconfirmed against this exact mainline DT
 * yet, so treat as inferred-not-measured until this node actually
 * probes. `epen_pdct_gts7l` (tlmm 7, "pen detect") has no equivalent
 * property in mainline's binding - the pinctrl state stays defined
 * but unused here; see the scoping doc for whether this turns out to
 * matter. reset-gpios omitted: downstream's node has no separate
 * reset line distinct from irq/pdct/fwe, and mainline's driver treats
 * it as optional (`devm_gpiod_get_optional`).
 *
 * vdd-supply: "pm8150_l13" (PM8150 LDO13), fixed at 3.296V - the
 * nearest representable step to stock's 3.3V. See the `pm8150_l13:
 * ldo13` node under `&apps_rsc`/`regulators-0` for why exactly 3.3V
 * can't be used and what the old "brownout" really was.
 *
 * Same recurring QUP-enablement pattern as i2c5/i2c8 above: i2c17's
 * parent QUP wrapper (`qupv3_id_2: geniqup@8c0000`) defaults to
 * `status = "disabled"` in sm8250.dtsi, and per the Round 48 finding
 * documented above (`&qupv3_id_1`), a disabled wrapper means none of
 * its children ever get instantiated regardless of their own status -
 * confirmed live here too (`ls /sys/bus/i2c/devices/` had no `17-*`
 * entry at all with only `&i2c17` itself enabled). i2c17's GENI SE
 * instance also has no FIFO mode (like i2c5, unlike i2c8) and needs a
 * real GPI DMA channel - its own `dmas` property points at
 * `&gpi_dma2`, a sibling of `qupv3_id_2`, not a child, so enabling the
 * wrapper alone doesn't cover it either. Following the exact same
 * `qcom,gpi-ee-offset` fix i2c5/gpi_dma0 needed (this SoC's downstream
 * firmware uses non-default TrustZone execution-environment bank
 * offsets per DMA controller instance, not the single hardcoded value
 * mainline's `drivers/dma/qcom/gpi.c` assumes) - real value pulled
 * directly from `references/gts7l/.../kona.dtsi:4722-4740`'s own
 * `gpi_dma2` node (`0x6000`, genuinely different from gpi_dma0's
 * `0x1000` - confirmed per-instance, not copied blindly).
 */
&qupv3_id_2 {
	status = "okay";
};

&gpi_dma2 {
	status = "okay";
	qcom,gpi-ee-offset = <0x6000>;
};

&i2c17 {
	status = "okay";

	wacom@56 {
		compatible = "wacom,w9021-gts7l";
		reg = <0x56>;

		pinctrl-names = "default";
		pinctrl-0 = <&epen_int_gts7l>, <&epen_fwe_gts7l>;

		interrupt-parent = <&tlmm>;
		/*
		 * Active-LOW (2026-09-22): downstream's wacom_i2c.c requests
		 * this line as IRQF_ONESHOT | IRQF_TRIGGER_LOW. It idles high
		 * (confirmed live, gpio136 reads high with no pen), so the
		 * original LEVEL_HIGH never delivered real pen events once
		 * the chip was actually powered.
		 */
		interrupts = <136 IRQ_TYPE_LEVEL_LOW>;

		/*
		 * Physical active area (2026-09-22): libinput refuses any
		 * tablet without an axis resolution ("missing tablet
		 * capabilities: resolution. Ignoring this device"), so KWin
		 * never opened the device and the chip was never powered.
		 * 11" 16:10 panel is ~237 x 148 mm; with the chip's reported
		 * 23585 x 14741 range that's ~99-100 units/mm, the usual
		 * Wacom EMR pitch. The driver derives resolution from these.
		 */
		touchscreen-x-mm = <237>;
		touchscreen-y-mm = <148>;

		/*
		 * Axis mapping to the panel's native (portrait, 1600x2560)
		 * orientation, from downstream's `wacom,invert = <1 0 1>`
		 * (x_invert, y_invert, xy_switch): wacom_i2c_coord_modify()
		 * inverts raw X first, then swaps - the same order mainline's
		 * touchscreen_apply_prop_to_x_y() uses for these properties.
		 * (Tilt isn't transformed by mainline; direction may be off.)
		 */
		touchscreen-inverted-x;
		touchscreen-swapped-x-y;

		vdd-supply = <&pm8150_l13>;
		/*
		 * Polarity test, RULED OUT (2026-09-21): flipping this from
		 * GPIO_ACTIVE_HIGH to GPIO_ACTIVE_LOW made no difference by
		 * itself - identical -ENXIO on real hardware, because the
		 * driver at the time always forced a static GPIOD_OUT_LOW
		 * and an unconditional power-cycle regardless of the line's
		 * real hardware state. Set back to GPIO_ACTIVE_HIGH here
		 * because that's what the downstream device tree for this
		 * exact chip uses for this same pin (wacom,fwe-gpio flag
		 * cell = 0x0, i.e. no active-low annotation) - confirmed by
		 * reading references/gts7l's kona-sec-gts7l-eur-overlay-r07
		 * (dtbo_idx=7, matching this device's own
		 * androidboot.dtbo_idx=7). The driver now reads this line's
		 * hardware-default value with GPIOD_ASIS before touching it
		 * and only forces a power-cycle if it was already high,
		 * matching that downstream driver's wacom_i2c_probe() branch
		 * exactly instead of guessing. See docs/phase4-spen-scoping.md.
		 */
		flash-mode-gpios = <&tlmm 6 GPIO_ACTIVE_HIGH>;
	};
};

/*
 * Audio stage 2 (2026-09-22, docs/phase3-audio-scoping.md): the four
 * Cirrus CS35L41 speaker amps, CONTROL ONLY. No machine driver or sound
 * card is built, so there is no audio path, no DSP/protection firmware is
 * loaded, and nothing sets an amp's GLOBAL_EN: at probe the driver only
 * resets each chip, applies its errata/OTP and programs the config below.
 *
 * Every value is taken from real hardware or stock's DT, none guessed:
 *  - bus: stock "i2c-7" = the controller at 0xa8c000 = mainline i2c11,
 *    gpio60/61 qup11 (same pins as downstream). Downstream runs it on GPI
 *    DMA via gpi_dma1, whose TrustZone EE offset is 0x6000
 *    (references/gts7l/.../kona.dtsi gpi_dma1). 400 kHz as stock's
 *    i2c-geni default.
 *  - boost: read read-only from all four amps in TWRP (Samsung kernel):
 *    BSTCVRT_COEFF 0x2424 and SLOPE_LBST 0x7500. Downstream never changes
 *    them; in mainline's cs35l41-lib tables that is exactly
 *    lbst_val 0 = 1.0 uH and cap range 0 (0-19 uF). Peak current is
 *    stock DT's cirrus,boost-peak-milliamp = <4100>. See
 *    docs/logs/audio-stage1-2026-09-22/.
 *  - asp-sdout-hiz = 3 as stock (all four share the TDM data line).
 *  - VA/VP: stock wires them to a dummy regulator (rails always on in
 *    hardware), so no supply properties.
 *  - IRQ: all four share gpio84. Stock sets GPIO2 to push-pull INTB on
 *    every amp, which on one shared line could drive against each other;
 *    open-drain INTB (src 2) with a SoC-side pull-up is the electrically
 *    safe equivalent (same active-low line, nothing can contend).
 *  - reset: one line, gpio69, shared by all four. Downstream declares it on
 *    cs35l41@43 only (`reset-gpios = <&tlmm 69 0>`, active-high = run);
 *    without it the chips sit in reset (gpio69 idles low with a pull-down)
 *    and NACK every address. It's on all four nodes here because mainline
 *    cs35l41 supports a shared reset that way: the first amp to probe
 *    owns it and releases it, the rest get -EBUSY and log "assuming shared
 *    reset". If probe fails, the error path drives it low again, holding
 *    all four silently in reset.
 */
&gpi_dma1 {
	status = "okay";
	qcom,gpi-ee-offset = <0x6000>;
};

&tlmm {
	cs35l41_irq_default: cs35l41-irq-state {
		pins = "gpio84";
		function = "gpio";
		bias-pull-up;
	};
};

&i2c11 {
	clock-frequency = <400000>;
	pinctrl-0 = <&qup_i2c11_default>, <&cs35l41_irq_default>;
	status = "okay";

	cs35l41_40: amplifier@40 {
		compatible = "cirrus,cs35l41";
		reg = <0x40>;
		#sound-dai-cells = <1>;
		sound-name-prefix = "RR";
		cirrus,subsystem-id = "gts7l";
		interrupt-parent = <&tlmm>;
		reset-gpios = <&tlmm 69 GPIO_ACTIVE_HIGH>;
		interrupts = <84 IRQ_TYPE_LEVEL_LOW>;
		cirrus,boost-peak-milliamp = <4100>;
		cirrus,boost-ind-nanohenry = <1000>;
		cirrus,boost-cap-microfarad = <10>;
		cirrus,asp-sdout-hiz = <3>;
		cirrus,gpio2-src-select = <2>;
		cirrus,gpio2-output-enable;
	};

	cs35l41_41: amplifier@41 {
		compatible = "cirrus,cs35l41";
		reg = <0x41>;
		#sound-dai-cells = <1>;
		sound-name-prefix = "RL";
		cirrus,subsystem-id = "gts7l";
		interrupt-parent = <&tlmm>;
		reset-gpios = <&tlmm 69 GPIO_ACTIVE_HIGH>;
		interrupts = <84 IRQ_TYPE_LEVEL_LOW>;
		cirrus,boost-peak-milliamp = <4100>;
		cirrus,boost-ind-nanohenry = <1000>;
		cirrus,boost-cap-microfarad = <10>;
		cirrus,asp-sdout-hiz = <3>;
		cirrus,gpio2-src-select = <2>;
		cirrus,gpio2-output-enable;
	};

	cs35l41_42: amplifier@42 {
		compatible = "cirrus,cs35l41";
		reg = <0x42>;
		#sound-dai-cells = <1>;
		sound-name-prefix = "FR";
		cirrus,subsystem-id = "gts7l";
		interrupt-parent = <&tlmm>;
		reset-gpios = <&tlmm 69 GPIO_ACTIVE_HIGH>;
		interrupts = <84 IRQ_TYPE_LEVEL_LOW>;
		cirrus,boost-peak-milliamp = <4100>;
		cirrus,boost-ind-nanohenry = <1000>;
		cirrus,boost-cap-microfarad = <10>;
		cirrus,asp-sdout-hiz = <3>;
		cirrus,gpio2-src-select = <2>;
		cirrus,gpio2-output-enable;
	};

	cs35l41_43: amplifier@43 {
		compatible = "cirrus,cs35l41";
		reg = <0x43>;
		#sound-dai-cells = <1>;
		sound-name-prefix = "FL";
		cirrus,subsystem-id = "gts7l";
		interrupt-parent = <&tlmm>;
		reset-gpios = <&tlmm 69 GPIO_ACTIVE_HIGH>;
		interrupts = <84 IRQ_TYPE_LEVEL_LOW>;
		cirrus,boost-peak-milliamp = <4100>;
		cirrus,boost-ind-nanohenry = <1000>;
		cirrus,boost-cap-microfarad = <10>;
		cirrus,asp-sdout-hiz = <3>;
		cirrus,gpio2-src-select = <2>;
		cirrus,gpio2-output-enable;
	};
};

/*
 * Audio stage 3 (2026-09-22, docs/phase3-audio-scoping.md "Stage 3/4
 * design"): the speaker sound card. Everything is from stock sources:
 *  - link: stock kona.c msm_tdm_be_dai_links[] PRI_TDM_RX_0 (AFE 36864),
 *    DSP_A, amps as clock consumers, IB_NF; 4 x 32-bit slots at 48 kHz
 *    (stock qcom,tdm-max-slots = <4>). The machine driver (sm8250.c,
 *    kernel/patches/0017) puts amp i on slot i in the codec order below,
 *    matching stock mixer_paths.xml ASPRX1 slots FL 0, FR 1, RL 2, RR 3.
 *  - port: stock qcom,msm-dai-tdm-pri-rx sync-mode 1, sync-src 1,
 *    data-out 0, invert-sync 1, data-delay 1, data-align 0.
 *  - pins: stock pri_tdm_* states - gpio138 mi2s0_sck, gpio141 mi2s0_ws,
 *    gpio140 mi2s0_data1 (data to the amps), gpio139 mi2s0_data0 (VI
 *    feedback), drive-strength 2, bias-disable.
 *  - codec order FL, FR, RL, RR = amps 0x43, 0x42, 0x41, 0x40 (stock MFD
 *    probe order + kona_tdm_cirrus_init's codec_dais[0..3]).
 *
 * SAFETY: the ALSA device nodes are root-only until protection is
 * verified (tools/rootfs/audio/72-gts7l-audio-gate.rules), and the amps'
 * "PCM Source" resets to ASP (protection bypassed) - it must be set to
 * DSP before any stream. See the scoping doc's hard rules.
 */
&tlmm {
	pri_tdm_active: pri-tdm-active-state {
		sck-pins {
			pins = "gpio138";
			function = "mi2s0_sck";
			drive-strength = <2>;
			bias-disable;
		};

		din-pins {
			pins = "gpio139";
			function = "mi2s0_data0";
			drive-strength = <2>;
			bias-disable;
		};

		dout-pins {
			pins = "gpio140";
			function = "mi2s0_data1";
			drive-strength = <2>;
			bias-disable;
		};

		ws-pins {
			pins = "gpio141";
			function = "mi2s0_ws";
			drive-strength = <2>;
			bias-disable;
		};
	};
};

&q6afedai {
	dai@24 {
		reg = <PRIMARY_TDM_RX_0>;
		qcom,tdm-sync-mode = <1>;
		qcom,tdm-sync-src = <1>;
		qcom,tdm-data-out = <0>;
		qcom,tdm-invert-sync = <1>;
		qcom,tdm-data-delay = <1>;
		qcom,tdm-data-align = <0>;
	};
};

&q6asmdai {
	dai@0 {
		reg = <MSM_FRONTEND_DAI_MULTIMEDIA1>;
	};
};

&sound {
	compatible = "qcom,sm8250-sndcard";
	model = "Samsung-GTS7L-CS35L41-Speakers";
	pinctrl-names = "default";
	pinctrl-0 = <&pri_tdm_active>;

	mm1-dai-link {
		link-name = "MultiMedia1";

		cpu {
			sound-dai = <&q6asmdai MSM_FRONTEND_DAI_MULTIMEDIA1>;
		};
	};

	speaker-dai-link {
		link-name = "Speaker Playback";

		cpu {
			sound-dai = <&q6afedai PRIMARY_TDM_RX_0>;
		};

		platform {
			sound-dai = <&q6routing>;
		};

		codec {
			sound-dai = <&cs35l41_43 0>, <&cs35l41_42 0>,
				    <&cs35l41_41 0>, <&cs35l41_40 0>;
		};
	};
};
